[part 2 of 6: package /DBC_SysDesc_P_CANFD/Pkg_Cluster]
AUTOSAR XML (schema 4-2-2)
package /DBC_SysDesc_P_CANFD/Pkg_Cluster  (continued)
  can cluster P_CANFD: baudrate=500000, protocol-name=CAN, can-fd-baudrate=2000000  (continued)
    can physical channel P_CANFD_Channel: comm-connectors=Conn_P_CANFD_MVCU  (continued)
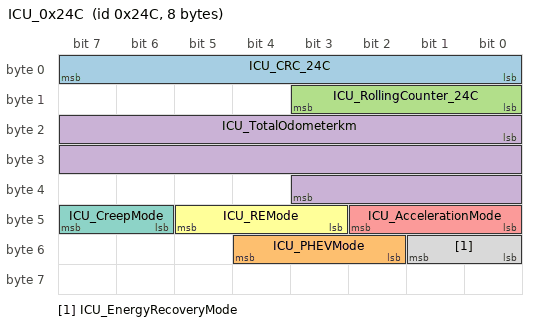
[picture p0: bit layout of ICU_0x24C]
      frame ICU_0x24C: id 0x24C, to MVCU, frame-length=8, can-addressing-mode=STANDARD, can-fd-frame-support=true, can-frame-rx-behavior=CAN-FD
        carries pdu ICU_0x24C: packing-byte-order=little-endian, start-position=0, update-indication-bit-position=-1
        pdu ICU_0x24C: length=8, transmission-mode-false-timing=cyclic-timing={time-offset=0.0, time-period=0.1}, transmission-mode-true-timing=cyclic-timing={time-offset=0.0, time-period=0.1}
          transmission-mode-conditions:
            {data-filter={data-filter-type=ALWAYS, max=255, min=0, offset=0}, i-signal-in-i-pdu=ICU_CRC_24C}
            {data-filter={data-filter-type=ALWAYS, max=7, min=0, offset=0}, i-signal-in-i-pdu=ICU_PHEVMode}
            {data-filter={data-filter-type=ALWAYS, max=15, min=0, offset=0}, i-signal-in-i-pdu=ICU_RollingCounter_24C}
            {data-filter={data-filter-type=NEW-IS-WITHIN, max=999999, min=0, offset=0}, i-signal-in-i-pdu=ICU_TotalOdometerkm}
            {data-filter={data-filter-type=ALWAYS, max=7, min=0, offset=0}, i-signal-in-i-pdu=ICU_AccelerationMode}
            {data-filter={data-filter-type=ALWAYS, max=7, min=0, offset=0}, i-signal-in-i-pdu=ICU_REMode}
            {data-filter={data-filter-type=ALWAYS, max=3, min=0, offset=0}, i-signal-in-i-pdu=ICU_CreepMode}
            {data-filter={data-filter-type=ALWAYS, max=3, min=0, offset=0}, i-signal-in-i-pdu=ICU_EnergyRecoveryMode}
          signal ICU_CRC_24C: start 0, 8 bit, little-endian, init-value=0, base-type=uint8, implementation-data-type=DT_ICU_CRC_24C, update-indication-bit-position=-1, to MVCU
          signal ICU_PHEVMode: start 50, 3 bit, little-endian, init-value=0, base-type=uint8, implementation-data-type=DT_ICU_PHEVMode, update-indication-bit-position=-1, to MVCU
          signal ICU_RollingCounter_24C: start 8, 4 bit, little-endian, init-value=0, base-type=uint8, implementation-data-type=DT_ICU_RollingCounter_24C, update-indication-bit-position=-1, to MVCU
          signal ICU_TotalOdometerkm: start 16, 20 bit, little-endian, init-value=0, base-type=uint32, implementation-data-type=DT_ICU_TotalOdometerkm, update-indication-bit-position=-1, to MVCU
          signal ICU_AccelerationMode: start 40, 3 bit, little-endian, init-value=0, base-type=uint8, implementation-data-type=DT_ICU_AccelerationMode, update-indication-bit-position=-1, to MVCU
          signal ICU_REMode: start 43, 3 bit, little-endian, init-value=0, base-type=uint8, implementation-data-type=DT_ICU_REMode, update-indication-bit-position=-1, to MVCU
          signal ICU_CreepMode: start 46, 2 bit, little-endian, init-value=0, base-type=uint8, implementation-data-type=DT_ICU_CreepMode, update-indication-bit-position=-1, to MVCU
          signal ICU_EnergyRecoveryMode: start 48, 2 bit, little-endian, init-value=0, base-type=uint8, implementation-data-type=DT_ICU_EnergyRecoveryMode, update-indication-bit-position=-1, to MVCU
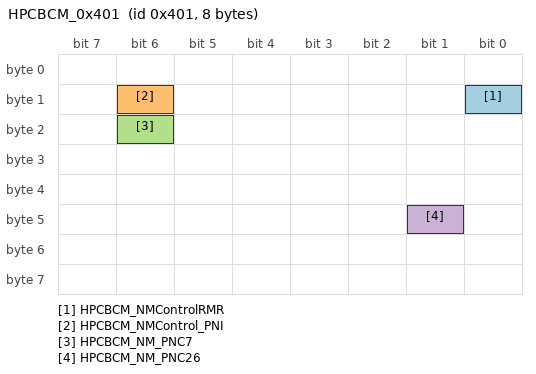
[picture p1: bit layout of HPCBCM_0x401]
      frame HPCBCM_0x401: id 0x401, to MVCU, frame-length=8, can-addressing-mode=STANDARD, can-fd-frame-support=true, can-frame-rx-behavior=CAN-FD
        carries pdu HPCBCM_0x401: packing-byte-order=little-endian, start-position=0, update-indication-bit-position=-1
        nm pdu HPCBCM_0x401: length=8, nm-data-information=false, nm-vote-information=false
          signal HPCBCM_NMControlRMR: start 8, 1 bit, little-endian, init-value=0, base-type=uint8, update-indication-bit-position=-1, to MVCU
          signal HPCBCM_NMControl_PNI: start 14, 1 bit, little-endian, init-value=0, base-type=uint8, update-indication-bit-position=-1, to MVCU
          signal HPCBCM_NM_PNC7: start 22, 1 bit, little-endian, init-value=0, base-type=uint8, update-indication-bit-position=-1, to MVCU
          signal HPCBCM_NM_PNC26: start 41, 1 bit, little-endian, init-value=0, base-type=uint8, update-indication-bit-position=-1, to MVCU
      frame IVI_0x34A: id 0x34A, to MVCU, frame-length=8, can-addressing-mode=STANDARD, can-fd-frame-support=true, can-frame-rx-behavior=CAN-FD
        carries pdu IVI_0x34A: packing-byte-order=little-endian, start-position=0, update-indication-bit-position=-1
        pdu IVI_0x34A: length=8
          transmission-mode-conditions:
            {data-filter={data-filter-type=ALWAYS, max=3, min=0, offset=0}, i-signal-in-i-pdu=IVI_DeliveryModeReq}
            {data-filter={data-filter-type=ALWAYS, max=3, min=0, offset=0}, i-signal-in-i-pdu=IVI_ShowCarModeReq}
          signal IVI_DeliveryModeReq: start 20, 2 bit, little-endian, init-value=0, base-type=uint8, implementation-data-type=DT_IVI_DeliveryModeReq, update-indication-bit-position=-1, to MVCU
          signal IVI_ShowCarModeReq: start 22, 2 bit, little-endian, init-value=0, base-type=uint8, implementation-data-type=DT_IVI_ShowCarModeReq, update-indication-bit-position=-1, to MVCU
      frame TMS_0x5A2: id 0x5A2, to MVCU, frame-length=64, can-addressing-mode=STANDARD, can-fd-frame-support=true, can-frame-rx-behavior=CAN-FD
        carries pdu TMS_0x5A2: packing-byte-order=little-endian, start-position=0, update-indication-bit-position=-1
        pdu TMS_0x5A2: length=64, transmission-mode-false-timing=cyclic-timing={time-offset=0.0, time-period=0.5}, transmission-mode-true-timing=cyclic-timing={time-offset=0.0, time-period=0.5}
          transmission-mode-conditions:
            {data-filter={data-filter-type=ALWAYS, max=250, min=0, offset=0}, i-signal-in-i-pdu=TMS_MainMotPumpSpdResp}
            {data-filter={data-filter-type=ALWAYS, max=250, min=0}, i-signal-in-i-pdu=TMS_MainMotPump_Operation_Temp}
            {data-filter={data-filter-type=ALWAYS, max=250, min=0, offset=0}, i-signal-in-i-pdu=TMS_MainMotPump_Operation_Current}
            {data-filter={data-filter-type=ALWAYS, max=254, min=0, offset=0}, i-signal-in-i-pdu=TMS_MainMotPump_Supplied_Voltage}
            {data-filter={data-filter-type=ALWAYS, max=15, min=0, offset=0}, i-signal-in-i-pdu=TMS_MainMotPumpErrSts}
          signal TMS_MainMotPumpSpdResp: start 24, 8 bit, little-endian, init-value=0, base-type=uint8, implementation-data-type=DT_TMS_MainMotPumpSpdResp, update-indication-bit-position=-1, to MVCU
          signal TMS_MainMotPump_Operation_Temp: start 32, 8 bit, little-endian, init-value=0, base-type=uint8, implementation-data-type=DT_TMS_MainMotPump_Operation_Temp, update-indication-bit-position=-1, to MVCU
          signal TMS_MainMotPump_Operation_Current: start 40, 8 bit, little-endian, init-value=0, base-type=uint8, implementation-data-type=DT_TMS_MainMotPump_Operation_Current, update-indication-bit-position=-1, to MVCU
          signal TMS_MainMotPump_Supplied_Voltage: start 48, 8 bit, little-endian, init-value=0, base-type=uint8, implementation-data-type=DT_TMS_MainMotPump_Supplied_Voltage, update-indication-bit-position=-1, to MVCU
          signal TMS_MainMotPumpErrSts: start 56, 4 bit, little-endian, init-value=0, base-type=uint8, implementation-data-type=DT_TMS_MainMotPumpErrSts, update-indication-bit-position=-1, to MVCU
      frame TMS_0x363: id 0x363, to MVCU, frame-length=16, can-addressing-mode=STANDARD, can-fd-frame-support=true, can-frame-rx-behavior=CAN-FD
        carries pdu TMS_0x363: packing-byte-order=little-endian, start-position=0, update-indication-bit-position=-1
        pdu TMS_0x363: length=16, transmission-mode-false-timing=cyclic-timing={time-offset=0.0, time-period=0.1}, transmission-mode-true-timing=cyclic-timing={time-offset=0.0, time-period=0.1}
          transmission-mode-conditions:
            {data-filter={data-filter-type=ALWAYS, max=15, min=0, offset=0}, i-signal-in-i-pdu=TMS_RollingCounter_363}
            {data-filter={data-filter-type=ALWAYS, max=1, min=0, offset=0}, i-signal-in-i-pdu=TMS_AC_Command}
            {data-filter={data-filter-type=ALWAYS, max=1, min=0, offset=0}, i-signal-in-i-pdu=TMS_PTCHeatingReq}
            {data-filter={data-filter-type=ALWAYS, max=200, min=0, offset=0}, i-signal-in-i-pdu=TMS_PTCPowerSet}
            {data-filter={data-filter-type=ALWAYS, max=1, min=0, offset=0}, i-signal-in-i-pdu=TMS_OutsideTempVD}
            {data-filter={data-filter-type=ALWAYS, max=254, min=0}, i-signal-in-i-pdu=TMS_OutsideTemp_Corrected}
          signal TMS_RollingCounter_363: start 0, 4 bit, little-endian, init-value=0, base-type=uint8, implementation-data-type=DT_TMS_RollingCounter_363, update-indication-bit-position=-1, to MVCU
          signal TMS_AC_Command: start 22, 1 bit, little-endian, init-value=0, base-type=uint8, implementation-data-type=DT_TMS_AC_Command, update-indication-bit-position=-1, to MVCU
          signal TMS_PTCHeatingReq: start 23, 1 bit, little-endian, init-value=0, base-type=uint8, implementation-data-type=DT_TMS_PTCHeatingReq, update-indication-bit-position=-1, to MVCU
          signal TMS_PTCPowerSet: start 32, 8 bit, little-endian, init-value=0, base-type=uint8, implementation-data-type=DT_TMS_PTCPowerSet, update-indication-bit-position=-1, to MVCU
          signal TMS_OutsideTempVD: start 55, 1 bit, little-endian, init-value=0, base-type=uint8, implementation-data-type=DT_TMS_OutsideTempVD, update-indication-bit-position=-1, to MVCU
          signal TMS_OutsideTemp_Corrected: start 64, 8 bit, little-endian, init-value=0, base-type=uint8, implementation-data-type=DT_TMS_OutsideTemp_Corrected, update-indication-bit-position=-1, to MVCU
      frame TMS_0x362: id 0x362, to MVCU, frame-length=32, can-addressing-mode=STANDARD, can-fd-frame-support=true, can-frame-rx-behavior=CAN-FD
        carries pdu TMS_0x362: packing-byte-order=little-endian, start-position=0, update-indication-bit-position=-1
        pdu TMS_0x362: length=32, transmission-mode-false-timing=cyclic-timing={time-offset=0.0, time-period=0.1}, transmission-mode-true-timing=cyclic-timing={time-offset=0.0, time-period=0.1}
          transmission-mode-conditions:
            {data-filter={data-filter-type=ALWAYS, max=3, min=0, offset=0}, i-signal-in-i-pdu=TMS_RAPTC_ModOprtgStsFrt}
            {data-filter={data-filter-type=ALWAYS, max=1, min=0, offset=0}, i-signal-in-i-pdu=TMS_RAPTC_ModOpEnblCmd}
            {data-filter={data-filter-type=ALWAYS, max=1023, min=0, offset=0}, i-signal-in-i-pdu=TMS_RAPTC_MsrdPwrFrt}
          signal TMS_RAPTC_ModOprtgStsFrt: start 144, 2 bit, little-endian, init-value=0, base-type=uint8, implementation-data-type=DT_TMS_RAPTC_ModOprtgStsFrt, update-indication-bit-position=-1, to MVCU
          signal TMS_RAPTC_ModOpEnblCmd: start 162, 1 bit, little-endian, init-value=0, base-type=uint8, implementation-data-type=DT_TMS_RAPTC_ModOpEnblCmd, update-indication-bit-position=-1, to MVCU
          signal TMS_RAPTC_MsrdPwrFrt: start 152, 10 bit, little-endian, init-value=0, base-type=uint16, implementation-data-type=DT_TMS_RAPTC_MsrdPwrFrt, update-indication-bit-position=-1, to MVCU
      frame ECM_0x148: id 0x148, to MVCU, frame-length=16, can-addressing-mode=STANDARD, can-fd-frame-support=true, can-frame-rx-behavior=CAN-FD
        carries pdu ECM_0x148: packing-byte-order=little-endian, start-position=0, update-indication-bit-position=-1
        pdu ECM_0x148: length=16, transmission-mode-false-timing=cyclic-timing={time-offset=0.0, time-period=1.0}, transmission-mode-true-timing=cyclic-timing={time-offset=0.0, time-period=1.0}
          transmission-mode-conditions:
            {data-filter={data-filter-type=ALWAYS, max=254, min=0, offset=0}, i-signal-in-i-pdu=ECM_SWVersionC}
            {data-filter={data-filter-type=ALWAYS, max=254, min=0, offset=0}, i-signal-in-i-pdu=ECM_SWVersionB}
            {data-filter={data-filter-type=ALWAYS, max=15, min=0, offset=0}, i-signal-in-i-pdu=ECM_SWVersionA}
            {data-filter={data-filter-type=NEW-IS-WITHIN, max=1677721600, min=0, offset=0}, i-signal-in-i-pdu=ECM_Total_fuel_consumed}
          signal ECM_SWVersionC: start 0, 8 bit, little-endian, init-value=0, base-type=uint8, implementation-data-type=DT_ECM_SWVersionC, update-indication-bit-position=-1, to MVCU
          signal ECM_SWVersionB: start 8, 8 bit, little-endian, init-value=0, base-type=uint8, implementation-data-type=DT_ECM_SWVersionB, update-indication-bit-position=-1, to MVCU
          signal ECM_SWVersionA: start 16, 4 bit, little-endian, init-value=0, base-type=uint8, implementation-data-type=DT_ECM_SWVersionA, update-indication-bit-position=-1, to MVCU
          signal ECM_Total_fuel_consumed: start 64, 32 bit, little-endian, init-value=0, base-type=uint32, implementation-data-type=DT_ECM_Total_fuel_consumed, update-indication-bit-position=-1, to MVCU
      frame IBS_0x225: id 0x225, to MVCU, frame-length=32, can-addressing-mode=STANDARD, can-fd-frame-support=true, can-frame-rx-behavior=CAN-FD
        carries pdu IBS_0x225: packing-byte-order=little-endian, start-position=0, update-indication-bit-position=-1
        pdu IBS_0x225: length=32, transmission-mode-false-timing=cyclic-timing={time-offset=0.0, time-period=0.02}, transmission-mode-true-timing=cyclic-timing={time-offset=0.0, time-period=0.02}
          transmission-mode-conditions:
            {data-filter={data-filter-type=ALWAYS, max=255, min=0, offset=0}, i-signal-in-i-pdu=IBS_CRC_225}
            {data-filter={data-filter-type=ALWAYS, max=15, min=0, offset=0}, i-signal-in-i-pdu=IBS_RollingCounter_225}
            {data-filter={data-filter-type=ALWAYS, max=3, min=0, offset=0}, i-signal-in-i-pdu=IBS_Warning_Level}
          signal IBS_CRC_225: start 0, 8 bit, little-endian, init-value=0, base-type=uint8, implementation-data-type=DT_IBS_CRC_225, update-indication-bit-position=-1, to MVCU
          signal IBS_RollingCounter_225: start 8, 4 bit, little-endian, init-value=0, base-type=uint8, implementation-data-type=DT_IBS_RollingCounter_225, update-indication-bit-position=-1, to MVCU
          signal IBS_Warning_Level: start 46, 2 bit, little-endian, init-value=0, base-type=uint8, implementation-data-type=DT_IBS_Warning_Level, update-indication-bit-position=-1, to MVCU
      frame HPCGW_0x3B1: id 0x3B1, to MVCU, frame-length=32, can-addressing-mode=STANDARD, can-fd-frame-support=true, can-frame-rx-behavior=CAN-FD
        carries pdu HPCGW_0x3B1: packing-byte-order=little-endian, start-position=0, update-indication-bit-position=-1
        pdu HPCGW_0x3B1: length=32, transmission-mode-false-timing=cyclic-timing={time-offset=0.0, time-period=0.1}, transmission-mode-true-timing=cyclic-timing={time-offset=0.0, time-period=0.1}
          transmission-mode-conditions:
            {data-filter={data-filter-type=ALWAYS, max=255, min=0, offset=0}, i-signal-in-i-pdu=GW_CRC_3B1}
            {data-filter={data-filter-type=ALWAYS, max=15, min=0, offset=0}, i-signal-in-i-pdu=GW_RollingCounter_3B1}
            {data-filter={data-filter-type=ALWAYS, max=3, min=0, offset=0}, i-signal-in-i-pdu=GW_ACU_FLSeatBeltRSt}
            {data-filter={data-filter-type=ALWAYS, max=3, min=0, offset=0}, i-signal-in-i-pdu=GW_ACU_FRSeatBeltRSt}
            {data-filter={data-filter-type=ALWAYS, max=7, min=0, offset=0}, i-signal-in-i-pdu=GW_IBC_EPB_Status}
            {data-filter={data-filter-type=ALWAYS, max=1, min=0, offset=0}, i-signal-in-i-pdu=GW_ACU_TotalCrashOutputSts}
            {data-filter={data-filter-type=ALWAYS, max=250, min=0}, i-signal-in-i-pdu=GW_BZCU_DCChgExitTemp_Pos}
            {data-filter={data-filter-type=ALWAYS, max=250, min=0}, i-signal-in-i-pdu=GW_BZCU_DCChgExitTemp_Neg}
            {data-filter={data-filter-type=ALWAYS, max=250, min=0}, i-signal-in-i-pdu=GW_BZCU_ACChgExitTemp_Pos}
            {data-filter={data-filter-type=ALWAYS, max=1, min=0, offset=0}, i-signal-in-i-pdu=GW_BZCU_FuelTankSts}
            {data-filter={data-filter-type=ALWAYS, max=180, min=0, offset=0}, i-signal-in-i-pdu=GW_BZCU_LBMS_VoltA}
            {data-filter={data-filter-type=ALWAYS, max=250, min=0}, i-signal-in-i-pdu=GW_BZCU_ACChgExitTemp_Neg}
            {data-filter={data-filter-type=ALWAYS, max=3, min=0, offset=0}, i-signal-in-i-pdu=GW_BZCU_FuelTankStsLockSts}
            {data-filter={data-filter-type=ALWAYS, max=3, min=0, offset=0}, i-signal-in-i-pdu=GW_BZCU_FuelTankLockCtrl}
            {data-filter={data-filter-type=ALWAYS, max=3, min=0, offset=0}, i-signal-in-i-pdu=GW_BZCU_ACChgLockSts}
            {data-filter={data-filter-type=ALWAYS, max=1, min=0, offset=0}, i-signal-in-i-pdu=GW_RZCU_Cabin_220Vconnect_Sts}
            {data-filter={data-filter-type=ALWAYS, max=1, min=0, offset=0}, i-signal-in-i-pdu=GW_BZCU_Cab_220VRelay_CtrlSts}
            {data-filter={data-filter-type=ALWAYS, max=1, min=0, offset=0}, i-signal-in-i-pdu=GW_BZCU_Cab_PDU220VRelay_CtrlSts}
            {data-filter={data-filter-type=ALWAYS, max=1, min=0, offset=0}, i-signal-in-i-pdu=GW_BZCU_Cabin_220VRelay_CtrlSts}
            {data-filter={data-filter-type=ALWAYS, max=1, min=0, offset=0}, i-signal-in-i-pdu=GW_BZCU_Cab_220Vconnect_Sts}
            {data-filter={data-filter-type=NEW-IS-WITHIN, max=11000, min=0}, i-signal-in-i-pdu=GW_TBOXSOC_Altitude}
          signal GW_CRC_3B1: start 0, 8 bit, little-endian, init-value=0, base-type=uint8, implementation-data-type=DT_GW_CRC_3B1, update-indication-bit-position=-1, to MVCU
          signal GW_RollingCounter_3B1: start 8, 4 bit, little-endian, init-value=0, base-type=uint8, implementation-data-type=DT_GW_RollingCounter_3B1, update-indication-bit-position=-1, to MVCU
          signal GW_ACU_FLSeatBeltRSt: start 16, 2 bit, little-endian, init-value=0, base-type=uint8, implementation-data-type=DT_GW_ACU_FLSeatBeltRSt, update-indication-bit-position=-1, to MVCU
          signal GW_ACU_FRSeatBeltRSt: start 18, 2 bit, little-endian, init-value=0, base-type=uint8, implementation-data-type=DT_GW_ACU_FRSeatBeltRSt, update-indication-bit-position=-1, to MVCU
          signal GW_IBC_EPB_Status: start 20, 3 bit, little-endian, init-value=0, base-type=uint8, implementation-data-type=DT_GW_IBC_EPB_Status, update-indication-bit-position=-1, to MVCU
          signal GW_ACU_TotalCrashOutputSts: start 40, 1 bit, little-endian, init-value=0, base-type=uint8, implementation-data-type=DT_GW_ACU_TotalCrashOutputSts, update-indication-bit-position=-1, to MVCU
          signal GW_BZCU_DCChgExitTemp_Pos: start 56, 8 bit, little-endian, init-value=0, base-type=uint8, implementation-data-type=DT_GW_BZCU_DCChgExitTemp_Pos, update-indication-bit-position=-1, to MVCU
          signal GW_BZCU_DCChgExitTemp_Neg: start 64, 8 bit, little-endian, init-value=0, base-type=uint8, implementation-data-type=DT_GW_BZCU_DCChgExitTemp_Neg, update-indication-bit-position=-1, to MVCU
          signal GW_BZCU_ACChgExitTemp_Pos: start 72, 8 bit, little-endian, init-value=0, base-type=uint8, implementation-data-type=DT_GW_BZCU_ACChgExitTemp_Pos, update-indication-bit-position=-1, to MVCU
          signal GW_BZCU_FuelTankSts: start 94, 1 bit, little-endian, init-value=0, base-type=uint8, implementation-data-type=DT_GW_BZCU_FuelTankSts, update-indication-bit-position=-1, to MVCU
          signal GW_BZCU_LBMS_VoltA: start 136, 8 bit, little-endian, init-value=0, base-type=uint8, implementation-data-type=DT_GW_BZCU_LBMS_VoltA, update-indication-bit-position=-1, to MVCU
          signal GW_BZCU_ACChgExitTemp_Neg: start 152, 8 bit, little-endian, init-value=0, base-type=uint8, implementation-data-type=DT_GW_BZCU_ACChgExitTemp_Neg, update-indication-bit-position=-1, to MVCU
          signal GW_BZCU_FuelTankStsLockSts: start 204, 2 bit, little-endian, init-value=0, base-type=uint8, implementation-data-type=DT_GW_BZCU_FuelTankStsLockSts, update-indication-bit-position=-1, to MVCU
          signal GW_BZCU_FuelTankLockCtrl: start 206, 2 bit, little-endian, init-value=0, base-type=uint8, implementation-data-type=DT_GW_BZCU_FuelTankLockCtrl, update-indication-bit-position=-1, to MVCU
          signal GW_BZCU_ACChgLockSts: start 208, 2 bit, little-endian, init-value=0, base-type=uint8, implementation-data-type=DT_GW_BZCU_ACChgLockSts, update-indication-bit-position=-1, to MVCU
          signal GW_RZCU_Cabin_220Vconnect_Sts: start 210, 1 bit, little-endian, init-value=0, base-type=uint8, implementation-data-type=DT_GW_RZCU_Cabin_220Vconnect_Sts, update-indication-bit-position=-1, to MVCU
          signal GW_BZCU_Cab_220VRelay_CtrlSts: start 211, 1 bit, little-endian, init-value=0, base-type=uint8, implementation-data-type=DT_GW_BZCU_Cab_220VRelay_CtrlSts, update-indication-bit-position=-1, to MVCU
          signal GW_BZCU_Cab_PDU220VRelay_CtrlSts: start 212, 1 bit, little-endian, init-value=0, base-type=uint8, implementation-data-type=DT_GW_BZCU_Cab_PDU220VRelay_CtrlSts, update-indication-bit-position=-1, to MVCU
          signal GW_BZCU_Cabin_220VRelay_CtrlSts: start 213, 1 bit, little-endian, init-value=0, base-type=uint8, implementation-data-type=DT_GW_BZCU_Cabin_220VRelay_CtrlSts, update-indication-bit-position=-1, to MVCU
          signal GW_BZCU_Cab_220Vconnect_Sts: start 214, 1 bit, little-endian, init-value=0, base-type=uint8, implementation-data-type=DT_GW_BZCU_Cab_220Vconnect_Sts, update-indication-bit-position=-1, to MVCU
          signal GW_TBOXSOC_Altitude: start 236, 14 bit, little-endian, init-value=0, base-type=uint16, implementation-data-type=DT_GW_TBOXSOC_Altitude, update-indication-bit-position=-1, to MVCU
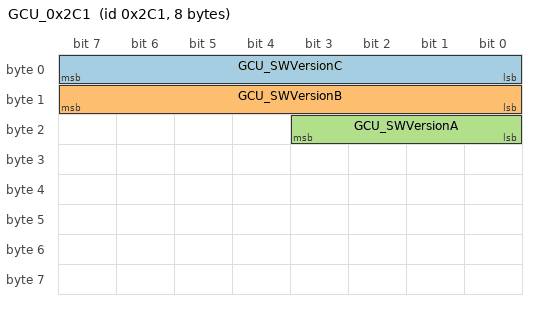
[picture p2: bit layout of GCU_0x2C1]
      frame GCU_0x2C1: id 0x2C1, to MVCU, frame-length=8, can-addressing-mode=STANDARD, can-fd-frame-support=true, can-frame-rx-behavior=CAN-FD
        carries pdu GCU_0x2C1: packing-byte-order=little-endian, start-position=0, update-indication-bit-position=-1
        pdu GCU_0x2C1: length=8, transmission-mode-false-timing=cyclic-timing={time-offset=0.0, time-period=0.1}, transmission-mode-true-timing=cyclic-timing={time-offset=0.0, time-period=0.1}
          transmission-mode-conditions:
            {data-filter={data-filter-type=ALWAYS, max=254, min=0, offset=0}, i-signal-in-i-pdu=GCU_SWVersionC}
            {data-filter={data-filter-type=ALWAYS, max=254, min=0, offset=0}, i-signal-in-i-pdu=GCU_SWVersionB}
            {data-filter={data-filter-type=ALWAYS, max=15, min=0, offset=0}, i-signal-in-i-pdu=GCU_SWVersionA}
          signal GCU_SWVersionC: start 0, 8 bit, little-endian, init-value=0, base-type=uint8, implementation-data-type=DT_GCU_SWVersionC, update-indication-bit-position=-1, to MVCU
          signal GCU_SWVersionB: start 8, 8 bit, little-endian, init-value=0, base-type=uint8, implementation-data-type=DT_GCU_SWVersionB, update-indication-bit-position=-1, to MVCU
          signal GCU_SWVersionA: start 16, 4 bit, little-endian, init-value=0, base-type=uint8, implementation-data-type=DT_GCU_SWVersionA, update-indication-bit-position=-1, to MVCU
      frame DCDC_0x324: id 0x324, to MVCU, frame-length=16, can-addressing-mode=STANDARD, can-fd-frame-support=true, can-frame-rx-behavior=CAN-FD
        carries pdu DCDC_0x324: packing-byte-order=little-endian, start-position=0, update-indication-bit-position=-1
        pdu DCDC_0x324: length=16, transmission-mode-false-timing=cyclic-timing={time-offset=0.0, time-period=0.1}, transmission-mode-true-timing=cyclic-timing={time-offset=0.0, time-period=0.1}
          transmission-mode-conditions:
            {data-filter={data-filter-type=ALWAYS, max=255, min=0, offset=0}, i-signal-in-i-pdu=DCDC_CRC_324}
            {data-filter={data-filter-type=ALWAYS, max=15, min=0, offset=0}, i-signal-in-i-pdu=DCDC_RollingCounter_324}
            {data-filter={data-filter-type=ALWAYS, max=3, min=0, offset=0}, i-signal-in-i-pdu=DCDC_WorkSts}
            {data-filter={data-filter-type=ALWAYS, max=1, min=0, offset=0}, i-signal-in-i-pdu=DCDC_Under_Output_Voltage}
            {data-filter={data-filter-type=ALWAYS, max=1, min=0, offset=0}, i-signal-in-i-pdu=DCDC_Over_Output_Voltage}
            {data-filter={data-filter-type=ALWAYS, max=1, min=0, offset=0}, i-signal-in-i-pdu=DCDC_Under_Input_Voltage}
            {data-filter={data-filter-type=ALWAYS, max=1, min=0, offset=0}, i-signal-in-i-pdu=DCDC_Over_Input_Voltage}
            {data-filter={data-filter-type=ALWAYS, max=1, min=0, offset=0}, i-signal-in-i-pdu=DCDC_Over_Input_Current}
            {data-filter={data-filter-type=NEW-IS-WITHIN, max=2500, min=0, offset=0}, i-signal-in-i-pdu=DCDC_Real_Output_Current}
            {data-filter={data-filter-type=NEW-IS-WITHIN, max=500, min=0, offset=0}, i-signal-in-i-pdu=DCDC_Real_Output_Voltage}
            {data-filter={data-filter-type=ALWAYS, max=100, min=0, offset=0}, i-signal-in-i-pdu=DCDC_Real_Input_Current}
            {data-filter={data-filter-type=NEW-IS-WITHIN, max=5000, min=0, offset=0}, i-signal-in-i-pdu=DCDC_Real_Input_Voltage}
            {data-filter={data-filter-type=ALWAYS, max=1, min=0, offset=0}, i-signal-in-i-pdu=DCDC_Derating}
            {data-filter={data-filter-type=ALWAYS, max=1, min=0, offset=0}, i-signal-in-i-pdu=DCDC_Hardware_Fault_Flag}
            {data-filter={data-filter-type=ALWAYS, max=1, min=0, offset=0}, i-signal-in-i-pdu=CDU_ACChg_HIVSts}
            {data-filter={data-filter-type=ALWAYS, max=1, min=0, offset=0}, i-signal-in-i-pdu=CDU_OBC_OverTemp}
            {data-filter={data-filter-type=ALWAYS, max=1, min=0, offset=0}, i-signal-in-i-pdu=CDU_SelfCheckSt}
            {data-filter={data-filter-type=ALWAYS, max=1, min=0, offset=0}, i-signal-in-i-pdu=CDU_HV_HIVSts}
          signal DCDC_CRC_324: start 0, 8 bit, little-endian, init-value=0, base-type=uint8, implementation-data-type=DT_DCDC_CRC_324, update-indication-bit-position=-1, to MVCU
          signal DCDC_RollingCounter_324: start 8, 4 bit, little-endian, init-value=0, base-type=uint8, implementation-data-type=DT_DCDC_RollingCounter_324, update-indication-bit-position=-1, to MVCU
          signal DCDC_WorkSts: start 16, 3 bit, little-endian, init-value=0, base-type=uint8, implementation-data-type=DT_DCDC_WorkSts, update-indication-bit-position=-1, to MVCU
          signal DCDC_Under_Output_Voltage: start 19, 1 bit, little-endian, init-value=0, base-type=uint8, implementation-data-type=DT_DCDC_Under_Output_Voltage, update-indication-bit-position=-1, to MVCU
          signal DCDC_Over_Output_Voltage: start 20, 1 bit, little-endian, init-value=0, base-type=uint8, implementation-data-type=DT_DCDC_Over_Output_Voltage, update-indication-bit-position=-1, to MVCU
          signal DCDC_Under_Input_Voltage: start 21, 1 bit, little-endian, init-value=0, base-type=uint8, implementation-data-type=DT_DCDC_Under_Input_Voltage, update-indication-bit-position=-1, to MVCU
          signal DCDC_Over_Input_Voltage: start 22, 1 bit, little-endian, init-value=0, base-type=uint8, implementation-data-type=DT_DCDC_Over_Input_Voltage, update-indication-bit-position=-1, to MVCU
          signal DCDC_Over_Input_Current: start 23, 1 bit, little-endian, init-value=0, base-type=uint8, implementation-data-type=DT_DCDC_Over_Input_Current, update-indication-bit-position=-1, to MVCU
          signal DCDC_Real_Output_Current: start 24, 12 bit, little-endian, init-value=0, base-type=uint16, implementation-data-type=DT_DCDC_Real_Output_Current, update-indication-bit-position=-1, to MVCU
          signal DCDC_Real_Output_Voltage: start 36, 12 bit, little-endian, init-value=0, base-type=uint16, implementation-data-type=DT_DCDC_Real_Output_Voltage, update-indication-bit-position=-1, to MVCU
          signal DCDC_Real_Input_Current: start 48, 8 bit, little-endian, init-value=0, base-type=uint8, implementation-data-type=DT_DCDC_Real_Input_Current, update-indication-bit-position=-1, to MVCU
          signal DCDC_Real_Input_Voltage: start 56, 13 bit, little-endian, init-value=0, base-type=uint16, implementation-data-type=DT_DCDC_Real_Input_Voltage, update-indication-bit-position=-1, to MVCU
          signal DCDC_Derating: start 69, 1 bit, little-endian, init-value=0, base-type=uint8, implementation-data-type=DT_DCDC_Derating, update-indication-bit-position=-1, to MVCU
          signal DCDC_Hardware_Fault_Flag: start 71, 1 bit, little-endian, init-value=0, base-type=uint8, implementation-data-type=DT_DCDC_Hardware_Fault_Flag, update-indication-bit-position=-1, to MVCU
          signal CDU_ACChg_HIVSts: start 83, 1 bit, little-endian, init-value=0, base-type=uint8, implementation-data-type=DT_CDU_ACChg_HIVSts, update-indication-bit-position=-1, to MVCU
          signal CDU_OBC_OverTemp: start 90, 1 bit, little-endian, init-value=0, base-type=uint8, implementation-data-type=DT_CDU_OBC_OverTemp, update-indication-bit-position=-1, to MVCU
          signal CDU_SelfCheckSt: start 112, 1 bit, little-endian, init-value=0, base-type=uint8, implementation-data-type=DT_CDU_SelfCheckSt, update-indication-bit-position=-1, to MVCU
          signal CDU_HV_HIVSts: start 113, 1 bit, little-endian, init-value=0, base-type=uint8, implementation-data-type=DT_CDU_HV_HIVSts, update-indication-bit-position=-1, to MVCU
      frame UDS_Phy_Rx_721_MCUM: id 0x721, to MVCU, frame-length=64, can-addressing-mode=STANDARD, can-fd-frame-support=true, can-frame-rx-behavior=CAN-FD
        carries pdu UDS_Phy_Rx_721_MCUM: packing-byte-order=big-endian, start-position=7, update-indication-bit-position=-1
        dcm i pdu UDS_Phy_Rx_721_MCUM: length=64, diag-pdu-type=DIAG-REQUEST
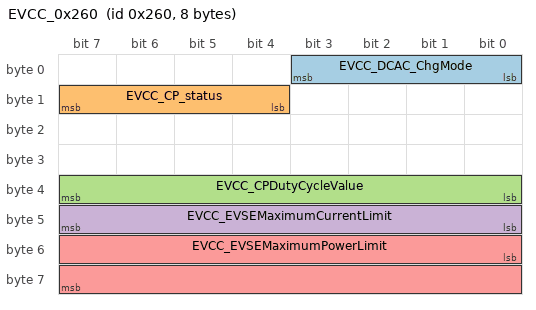
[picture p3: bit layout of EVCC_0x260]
      frame EVCC_0x260: id 0x260, to MVCU, frame-length=8, can-addressing-mode=STANDARD, can-fd-frame-support=true, can-frame-rx-behavior=CAN-FD
        carries pdu EVCC_0x260: packing-byte-order=little-endian, start-position=0, update-indication-bit-position=-1
        pdu EVCC_0x260: length=8, transmission-mode-false-timing=cyclic-timing={time-offset=0.0, time-period=0.1}, transmission-mode-true-timing=cyclic-timing={time-offset=0.0, time-period=0.1}
          transmission-mode-conditions:
            {data-filter={data-filter-type=ALWAYS, max=14, min=0, offset=0}, i-signal-in-i-pdu=EVCC_DCAC_ChgMode}
            {data-filter={data-filter-type=ALWAYS, max=14, min=0, offset=0}, i-signal-in-i-pdu=EVCC_CP_status}
            {data-filter={data-filter-type=ALWAYS, max=100, min=0, offset=0}, i-signal-in-i-pdu=EVCC_CPDutyCycleValue}
            {data-filter={data-filter-type=ALWAYS, max=254, min=0, offset=0}, i-signal-in-i-pdu=EVCC_EVSEMaximumCurrentLimit}
            {data-filter={data-filter-type=NEW-IS-WITHIN, max=65000, min=0, offset=0}, i-signal-in-i-pdu=EVCC_EVSEMaximumPowerLimit}
          signal EVCC_DCAC_ChgMode: start 0, 4 bit, little-endian, init-value=0, base-type=uint8, implementation-data-type=DT_EVCC_DCAC_ChgMode, update-indication-bit-position=-1, to MVCU
          signal EVCC_CP_status: start 12, 4 bit, little-endian, init-value=0, base-type=uint8, implementation-data-type=DT_EVCC_CP_status, update-indication-bit-position=-1, to MVCU
          signal EVCC_CPDutyCycleValue: start 32, 8 bit, little-endian, init-value=0, base-type=uint8, implementation-data-type=DT_EVCC_CPDutyCycleValue, update-indication-bit-position=-1, to MVCU
          signal EVCC_EVSEMaximumCurrentLimit: start 40, 8 bit, little-endian, init-value=0, base-type=uint8, implementation-data-type=DT_EVCC_EVSEMaximumCurrentLimit, update-indication-bit-position=-1, to MVCU
          signal EVCC_EVSEMaximumPowerLimit: start 48, 16 bit, little-endian, init-value=0, base-type=uint16, implementation-data-type=DT_EVCC_EVSEMaximumPowerLimit, update-indication-bit-position=-1, to MVCU
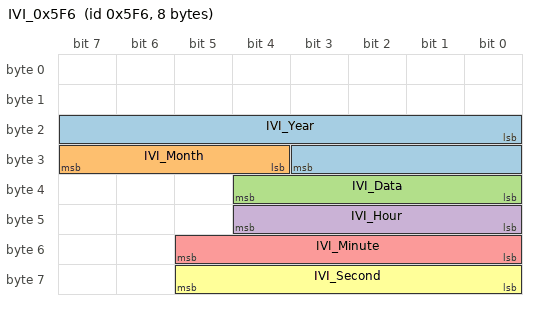
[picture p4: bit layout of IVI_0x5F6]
      frame IVI_0x5F6: id 0x5F6, to MVCU, frame-length=8, can-addressing-mode=STANDARD, can-fd-frame-support=true, can-frame-rx-behavior=CAN-FD
        carries pdu IVI_0x5F6: packing-byte-order=little-endian, start-position=0, update-indication-bit-position=-1
        pdu IVI_0x5F6: length=8, transmission-mode-false-timing=cyclic-timing={time-offset=0.0, time-period=0.5}, transmission-mode-true-timing=cyclic-timing={time-offset=0.0, time-period=0.5}
          transmission-mode-conditions:
            {data-filter={data-filter-type=NEW-IS-WITHIN, max=4094, min=0, offset=0}, i-signal-in-i-pdu=IVI_Year}
            {data-filter={data-filter-type=ALWAYS, max=12, min=0, offset=0}, i-signal-in-i-pdu=IVI_Month}
            {data-filter={data-filter-type=ALWAYS, max=31, min=0, offset=0}, i-signal-in-i-pdu=IVI_Data}
            {data-filter={data-filter-type=ALWAYS, max=23, min=0, offset=0}, i-signal-in-i-pdu=IVI_Hour}
            {data-filter={data-filter-type=ALWAYS, max=59, min=0, offset=0}, i-signal-in-i-pdu=IVI_Minute}
            {data-filter={data-filter-type=ALWAYS, max=59, min=0, offset=0}, i-signal-in-i-pdu=IVI_Second}
          signal IVI_Year: start 16, 12 bit, little-endian, init-value=0, base-type=uint16, implementation-data-type=DT_IVI_Year, update-indication-bit-position=-1, to MVCU
          signal IVI_Month: start 28, 4 bit, little-endian, init-value=0, base-type=uint8, implementation-data-type=DT_IVI_Month, update-indication-bit-position=-1, to MVCU
          signal IVI_Data: start 32, 5 bit, little-endian, init-value=0, base-type=uint8, implementation-data-type=DT_IVI_Data, update-indication-bit-position=-1, to MVCU
          signal IVI_Hour: start 40, 5 bit, little-endian, init-value=0, base-type=uint8, implementation-data-type=DT_IVI_Hour, update-indication-bit-position=-1, to MVCU
          signal IVI_Minute: start 48, 6 bit, little-endian, init-value=0, base-type=uint8, implementation-data-type=DT_IVI_Minute, update-indication-bit-position=-1, to MVCU
          signal IVI_Second: start 56, 6 bit, little-endian, init-value=0, base-type=uint8, implementation-data-type=DT_IVI_Second, update-indication-bit-position=-1, to MVCU
      frame MCU_0x5CB: id 0x5CB, from MVCU, frame-length=8, can-addressing-mode=STANDARD, can-fd-frame-support=true, can-frame-tx-behavior=CAN-FD
        carries pdu MCU_0x5CB: packing-byte-order=little-endian, start-position=0, update-indication-bit-position=-1
        pdu MCU_0x5CB: length=8, transmission-mode-false-timing=cyclic-timing={time-offset=0.0, time-period=0.01}, transmission-mode-true-timing=cyclic-timing={time-offset=0.0, time-period=0.01}
          transmission-mode-conditions:
            {data-filter={data-filter-type=ALWAYS, max=2, min=0, offset=0}, i-signal-in-i-pdu=GTC_TestSts}
            {data-filter={data-filter-type=NEW-IS-WITHIN, max=36000, min=0, offset=0}, i-signal-in-i-pdu=GTC_ThetaPos}
            {data-filter={data-filter-type=NEW-IS-WITHIN, max=36000, min=0, offset=0}, i-signal-in-i-pdu=GTC_ThetaNeg}
            {data-filter={data-filter-type=NEW-IS-WITHIN, max=36000, min=0, offset=0}, i-signal-in-i-pdu=GTC_ThetaDelt}
            {data-filter={data-filter-type=ALWAYS, max=1, min=0, offset=0}, i-signal-in-i-pdu=GTC_TestRslt}
            {data-filter={data-filter-type=ALWAYS, max=2, min=0, offset=0}, i-signal-in-i-pdu=MCUMR_GTC_TestSts}
            {data-filter={data-filter-type=NEW-IS-WITHIN, max=36000, min=0, offset=0}, i-signal-in-i-pdu=MCUMR_GTC_ThetaPos}
            {data-filter={data-filter-type=NEW-IS-WITHIN, max=36000, min=0, offset=0}, i-signal-in-i-pdu=MCUMR_GTC_ThetaNeg}
            {data-filter={data-filter-type=NEW-IS-WITHIN, max=36000, min=0, offset=0}, i-signal-in-i-pdu=MCUMR_GTC_ThetaDelt}
            {data-filter={data-filter-type=ALWAYS, max=1, min=0, offset=0}, i-signal-in-i-pdu=MCUMR_GTC_TestRslt}
          signal GTC_TestSts: start 0, 8 bit, little-endian, init-value=0, base-type=uint8, implementation-data-type=DT_GTC_TestSts, update-indication-bit-position=-1
          signal GTC_ThetaPos: start 8, 16 bit, little-endian, init-value=0, base-type=uint16, implementation-data-type=DT_GTC_ThetaPos, update-indication-bit-position=-1
          signal GTC_ThetaNeg: start 24, 16 bit, little-endian, init-value=0, base-type=uint16, implementation-data-type=DT_GTC_ThetaNeg, update-indication-bit-position=-1
          signal GTC_ThetaDelt: start 40, 16 bit, little-endian, init-value=0, base-type=uint16, implementation-data-type=DT_GTC_ThetaDelt, update-indication-bit-position=-1
          signal GTC_TestRslt: start 56, 8 bit, little-endian, init-value=0, base-type=uint8, implementation-data-type=DT_GTC_TestRslt, update-indication-bit-position=-1
          signal MCUMR_GTC_TestSts: start 64, 8 bit, little-endian, init-value=0, base-type=uint8, implementation-data-type=DT_MCUMR_GTC_TestSts, update-indication-bit-position=-1
          signal MCUMR_GTC_ThetaPos: start 72, 16 bit, little-endian, init-value=0, base-type=uint16, implementation-data-type=DT_MCUMR_GTC_ThetaPos, update-indication-bit-position=-1
          signal MCUMR_GTC_ThetaNeg: start 88, 16 bit, little-endian, init-value=0, base-type=uint16, implementation-data-type=DT_MCUMR_GTC_ThetaNeg, update-indication-bit-position=-1
          signal MCUMR_GTC_ThetaDelt: start 104, 16 bit, little-endian, init-value=0, base-type=uint16, implementation-data-type=DT_MCUMR_GTC_ThetaDelt, update-indication-bit-position=-1
          signal MCUMR_GTC_TestRslt: start 120, 8 bit, little-endian, init-value=0, base-type=uint8, implementation-data-type=DT_MCUMR_GTC_TestRslt, update-indication-bit-position=-1
      frame MCU_0x5CA: id 0x5CA, from MVCU, frame-length=32, can-addressing-mode=STANDARD, can-fd-frame-support=true, can-frame-tx-behavior=CAN-FD
        carries pdu MCU_0x5CA: packing-byte-order=little-endian, start-position=0, update-indication-bit-position=-1
        pdu MCU_0x5CA: length=32, transmission-mode-false-timing=cyclic-timing={time-offset=0.0, time-period=0.01}, transmission-mode-true-timing=cyclic-timing={time-offset=0.0, time-period=0.01}
          transmission-mode-conditions:
            {data-filter={data-filter-type=NEW-IS-WITHIN, max=4048, min=48}, i-signal-in-i-pdu=EddyCur_Para_Cos_m}
            {data-filter={data-filter-type=ALWAYS, max=5, min=0, offset=0}, i-signal-in-i-pdu=EddyCur_Stage}
            {data-filter={data-filter-type=ALWAYS, max=1, min=0, offset=0}, i-signal-in-i-pdu=EddyCur_IdenFinish_Flag}
            {data-filter={data-filter-type=NEW-IS-WITHIN, max=4048, min=48}, i-signal-in-i-pdu=EddyCur_Para_Sin_m}
            {data-filter={data-filter-type=ALWAYS, max=1, min=0, offset=0}, i-signal-in-i-pdu=EddyCur_Write_Flag}
            {data-filter={data-filter-type=ALWAYS, max=1, min=0, offset=0}, i-signal-in-i-pdu=EddyCur_FauPro_IDEL_OTime_Flag}
            {data-filter={data-filter-type=ALWAYS, max=1, min=0, offset=0}, i-signal-in-i-pdu=EddyCur_FauPro_SpdInstab_Flag}
            {data-filter={data-filter-type=ALWAYS, max=1, min=0, offset=0}, i-signal-in-i-pdu=EddyCur_FauPro_IDPara_OVal_Flag}
            {data-filter={data-filter-type=NEW-IS-WITHIN, max=30000, min=0, offset=0}, i-signal-in-i-pdu=EddyCur_Para_Cos_k}
            {data-filter={data-filter-type=ALWAYS, max=1, min=0, offset=0}, i-signal-in-i-pdu=EddyCur_Enable}
            {data-filter={data-filter-type=NEW-IS-WITHIN, max=30000, min=0, offset=0}, i-signal-in-i-pdu=EddyCur_Para_Sin_k}
            {data-filter={data-filter-type=ALWAYS, max=1, min=0, offset=0}, i-signal-in-i-pdu=EddyCur_IdenFail_Flag}
            {data-filter={data-filter-type=NEW-IS-WITHIN, max=40000, min=0}, i-signal-in-i-pdu=EddyCur_Para_Cos_Pha}
            {data-filter={data-filter-type=NEW-IS-WITHIN, max=40000, min=0}, i-signal-in-i-pdu=EddyCur_Para_Sin_Pha}
            {data-filter={data-filter-type=ALWAYS, max=1, min=0, offset=0}, i-signal-in-i-pdu=EddyCur_ReadSuccess_Flag}
            {data-filter={data-filter-type=ALWAYS, max=1, min=0, offset=0}, i-signal-in-i-pdu=OfsIden_ReadSuccess_Flag}
            {data-filter={data-filter-type=ALWAYS, max=1, min=0, offset=0}, i-signal-in-i-pdu=OfsIden_SpdUp_Overtime}
            {data-filter={data-filter-type=ALWAYS, max=1, min=0, offset=0}, i-signal-in-i-pdu=OfsIden_SpdUp_OverSpd}
            {data-filter={data-filter-type=ALWAYS, max=1, min=0, offset=0}, i-signal-in-i-pdu=OfsIden_IdenDiverge}
            {data-filter={data-filter-type=ALWAYS, max=1, min=0, offset=0}, i-signal-in-i-pdu=OfsIden_IdenCntOver}
            {data-filter={data-filter-type=ALWAYS, max=1, min=0, offset=0}, i-signal-in-i-pdu=OfsIden_MtrLock}
            {data-filter={data-filter-type=NEW-IS-WITHIN, max=3600, min=0, offset=0}, i-signal-in-i-pdu=OfsIden_OfsRslt}
            {data-filter={data-filter-type=ALWAYS, max=7, min=0, offset=0}, i-signal-in-i-pdu=OfsIden_Sts}
            {data-filter={data-filter-type=ALWAYS, max=1, min=0, offset=0}, i-signal-in-i-pdu=OfsIden_Finish}
            {data-filter={data-filter-type=ALWAYS, max=1, min=0, offset=0}, i-signal-in-i-pdu=OfsIden_OfsWrite_Finish}
            {data-filter={data-filter-type=ALWAYS, max=1, min=0, offset=0}, i-signal-in-i-pdu=OfsIden_DirWrite_Finish}
            {data-filter={data-filter-type=ALWAYS, max=2, min=0}, i-signal-in-i-pdu=OfsIden_DirIden_Rslt}
            {data-filter={data-filter-type=ALWAYS, max=1, min=0, offset=0}, i-signal-in-i-pdu=OfsIden_ZeroAlign_OverTime}
            {data-filter={data-filter-type=ALWAYS, max=1, min=0, offset=0}, i-signal-in-i-pdu=OfsIden_ZeroAlign_Fail}
            {data-filter={data-filter-type=ALWAYS, max=1, min=0, offset=0}, i-signal-in-i-pdu=OfsIden_IFStart_Overtime}
            {data-filter={data-filter-type=ALWAYS, max=1, min=0, offset=0}, i-signal-in-i-pdu=OfsIden_IFStart_Fail}
            {data-filter={data-filter-type=NEW-IS-WITHIN, max=60000, min=0}, i-signal-in-i-pdu=PosDly_Cal_RslvDelayTime}
            {data-filter={data-filter-type=NEW-IS-WITHIN, max=20000, min=0}, i-signal-in-i-pdu=PosDly_Theta_k_Std}
            {data-filter={data-filter-type=ALWAYS, max=1, min=0, offset=0}, i-signal-in-i-pdu=PosDly_Supplier}
            {data-filter={data-filter-type=ALWAYS, max=1, min=0, offset=0}, i-signal-in-i-pdu=PosDly_FauPro_Ident_OTm_Flag}
            {data-filter={data-filter-type=ALWAYS, max=1, min=0, offset=0}, i-signal-in-i-pdu=PosDly_FauPro_SpdDn_OTm_Flag}
            {data-filter={data-filter-type=ALWAYS, max=60, min=0}, i-signal-in-i-pdu=PosDly_RslvOffsetComp}
            {data-filter={data-filter-type=ALWAYS, max=1, min=0, offset=0}, i-signal-in-i-pdu=PosDly_Enable}
            {data-filter={data-filter-type=ALWAYS, max=1, min=0, offset=0}, i-signal-in-i-pdu=PosDly_IdentFail_Flag}
            {data-filter={data-filter-type=ALWAYS, max=1, min=0, offset=0}, i-signal-in-i-pdu=PosDly_IdentFinish_Flag}
            {data-filter={data-filter-type=ALWAYS, max=1, min=0, offset=0}, i-signal-in-i-pdu=PosDly_Write_Flag}
            {data-filter={data-filter-type=ALWAYS, max=1, min=0, offset=0}, i-signal-in-i-pdu=PosDly_FauPro_Chk_DlyTime_OVal}
            {data-filter={data-filter-type=ALWAYS, max=1, min=0, offset=0}, i-signal-in-i-pdu=PosDly_FauPro_Chk_RslvOfst_OVal}
            {data-filter={data-filter-type=ALWAYS, max=1, min=0, offset=0}, i-signal-in-i-pdu=PosDly_FauPro_Check_Divergence}
            {data-filter={data-filter-type=ALWAYS, max=1, min=0, offset=0}, i-signal-in-i-pdu=PosDly_FauPro_SpdUp_OTm_Flag}
            {data-filter={data-filter-type=ALWAYS, max=6, min=0, offset=0}, i-signal-in-i-pdu=PosDly_Stage}
            {data-filter={data-filter-type=ALWAYS, max=10, min=0, offset=0}, i-signal-in-i-pdu=IMParaIdent_ParEstMainStep}
            {data-filter={data-filter-type=NEW-IS-WITHIN, max=1000, min=0, offset=0}, i-signal-in-i-pdu=IMParaIdent_Rs}
            {data-filter={data-filter-type=NEW-IS-WITHIN, max=1000, min=0, offset=0}, i-signal-in-i-pdu=IMParaIdent_Rr}
            {data-filter={data-filter-type=NEW-IS-WITHIN, max=10000, min=0, offset=0}, i-signal-in-i-pdu=IMParaIdent_Ll}
            {data-filter={data-filter-type=NEW-IS-WITHIN, max=10000, min=0, offset=0}, i-signal-in-i-pdu=IMParaIdent_Lm}
            {data-filter={data-filter-type=NEW-IS-WITHIN, max=10000, min=0, offset=0}, i-signal-in-i-pdu=IMParaIdent_TotalLo}
            {data-filter={data-filter-type=ALWAYS, max=30, min=0, offset=0}, i-signal-in-i-pdu=IMParaIdent_IdentSubStep}
            {data-filter={data-filter-type=NEW-IS-WITHIN, max=4048, min=48}, i-signal-in-i-pdu=MCUMR_EddyCur_Para_Cos_m}
            {data-filter={data-filter-type=ALWAYS, max=5, min=0, offset=0}, i-signal-in-i-pdu=MCUMR_EddyCur_Stage}
            {data-filter={data-filter-type=ALWAYS, max=1, min=0, offset=0}, i-signal-in-i-pdu=MCUMR_EddyCur_IdenFinish_Flag}
            {data-filter={data-filter-type=NEW-IS-WITHIN, max=4048, min=48}, i-signal-in-i-pdu=MCUMR_EddyCur_Para_Sin_m}
            {data-filter={data-filter-type=ALWAYS, max=1, min=0, offset=0}, i-signal-in-i-pdu=MCUMR_EddyCur_Write_Flag}
            {data-filter={data-filter-type=ALWAYS, max=1, min=0, offset=0}, i-signal-in-i-pdu=MCUMR_EddyCur_FauPro_IDEL_OTime_Flag}
            {data-filter={data-filter-type=ALWAYS, max=1, min=0, offset=0}, i-signal-in-i-pdu=MCUMR_EddyCur_FauPro_SpdInstab_Flag}
            {data-filter={data-filter-type=ALWAYS, max=1, min=0, offset=0}, i-signal-in-i-pdu=MCUMR_EddyCur_FauPro_IDPara_OVal_Flag}
            {data-filter={data-filter-type=NEW-IS-WITHIN, max=30000, min=0, offset=0}, i-signal-in-i-pdu=MCUMR_EddyCur_Para_Cos_k}
            {data-filter={data-filter-type=ALWAYS, max=1, min=0, offset=0}, i-signal-in-i-pdu=MCUMR_EddyCur_Enable}
            {data-filter={data-filter-type=NEW-IS-WITHIN, max=30000, min=0, offset=0}, i-signal-in-i-pdu=MCUMR_EddyCur_Para_Sin_k}
            {data-filter={data-filter-type=ALWAYS, max=1, min=0, offset=0}, i-signal-in-i-pdu=MCUMR_EddyCur_IdenFail_Flag}
            {data-filter={data-filter-type=NEW-IS-WITHIN, max=40000, min=0}, i-signal-in-i-pdu=MCUMR_EddyCur_Para_Cos_Pha}
            {data-filter={data-filter-type=NEW-IS-WITHIN, max=40000, min=0}, i-signal-in-i-pdu=MCUMR_EddyCur_Para_Sin_Pha}
            {data-filter={data-filter-type=ALWAYS, max=1, min=0, offset=0}, i-signal-in-i-pdu=MCUMR_EddyCur_ReadSuccess_Flag}
            {data-filter={data-filter-type=ALWAYS, max=1, min=0, offset=0}, i-signal-in-i-pdu=MCUMR_OfsIden_ReadSuccess_Flag}
            {data-filter={data-filter-type=ALWAYS, max=1, min=0, offset=0}, i-signal-in-i-pdu=MCUMR_OfsIden_SpdUp_Overtime}
            {data-filter={data-filter-type=ALWAYS, max=1, min=0, offset=0}, i-signal-in-i-pdu=MCUMR_OfsIden_SpdUp_OverSpd}
            {data-filter={data-filter-type=ALWAYS, max=1, min=0, offset=0}, i-signal-in-i-pdu=MCUMR_OfsIden_IdenDiverge}
            {data-filter={data-filter-type=ALWAYS, max=1, min=0, offset=0}, i-signal-in-i-pdu=MCUMR_OfsIden_IdenCntOver}
            {data-filter={data-filter-type=ALWAYS, max=1, min=0, offset=0}, i-signal-in-i-pdu=MCUMR_OfsIden_MtrLock}
            {data-filter={data-filter-type=NEW-IS-WITHIN, max=3600, min=0, offset=0}, i-signal-in-i-pdu=MCUMR_OfsIden_OfsRslt}
            {data-filter={data-filter-type=ALWAYS, max=7, min=0, offset=0}, i-signal-in-i-pdu=MCUMR_OfsIden_Sts}
            {data-filter={data-filter-type=ALWAYS, max=1, min=0, offset=0}, i-signal-in-i-pdu=MCUMR_OfsIden_Finish}
            {data-filter={data-filter-type=ALWAYS, max=1, min=0, offset=0}, i-signal-in-i-pdu=MCUMR_OfsIden_OfsWrite_Finish}
            {data-filter={data-filter-type=ALWAYS, max=1, min=0, offset=0}, i-signal-in-i-pdu=MCUMR_OfsIden_DirWrite_Finish}
            {data-filter={data-filter-type=ALWAYS, max=2, min=0}, i-signal-in-i-pdu=MCUMR_OfsIden_DirIden_Rslt}
            {data-filter={data-filter-type=ALWAYS, max=1, min=0, offset=0}, i-signal-in-i-pdu=MCUMR_OfsIden_ZeroAlign_OverTime}
            {data-filter={data-filter-type=ALWAYS, max=1, min=0, offset=0}, i-signal-in-i-pdu=MCUMR_OfsIden_ZeroAlign_Fail}
            {data-filter={data-filter-type=ALWAYS, max=1, min=0, offset=0}, i-signal-in-i-pdu=MCUMR_OfsIden_IFStart_Overtime}
            {data-filter={data-filter-type=ALWAYS, max=1, min=0, offset=0}, i-signal-in-i-pdu=MCUMR_OfsIden_IFStart_Fail}
          signal EddyCur_Para_Cos_m: start 0, 12 bit, little-endian, init-value=0, base-type=uint16, implementation-data-type=DT_EddyCur_Para_Cos_m, update-indication-bit-position=-1
          signal EddyCur_Stage: start 12, 3 bit, little-endian, init-value=0, base-type=uint8, implementation-data-type=DT_EddyCur_Stage, update-indication-bit-position=-1
          signal EddyCur_IdenFinish_Flag: start 15, 1 bit, little-endian, init-value=0, base-type=uint8, implementation-data-type=DT_EddyCur_IdenFinish_Flag, update-indication-bit-position=-1
          signal EddyCur_Para_Sin_m: start 16, 12 bit, little-endian, init-value=0, base-type=uint16, implementation-data-type=DT_EddyCur_Para_Sin_m, update-indication-bit-position=-1
          signal EddyCur_Write_Flag: start 28, 1 bit, little-endian, init-value=0, base-type=uint8, implementation-data-type=DT_EddyCur_Write_Flag, update-indication-bit-position=-1
          signal EddyCur_FauPro_IDEL_OTime_Flag: start 29, 1 bit, little-endian, init-value=0, base-type=uint8, implementation-data-type=DT_EddyCur_FauPro_IDEL_OTime_Flag, update-indication-bit-position=-1
          signal EddyCur_FauPro_SpdInstab_Flag: start 30, 1 bit, little-endian, init-value=0, base-type=uint8, implementation-data-type=DT_EddyCur_FauPro_SpdInstab_Flag, update-indication-bit-position=-1
          signal EddyCur_FauPro_IDPara_OVal_Flag: start 31, 1 bit, little-endian, init-value=0, base-type=uint8, implementation-data-type=DT_EddyCur_FauPro_IDPara_OVal_Flag, update-indication-bit-position=-1
          signal EddyCur_Para_Cos_k: start 32, 15 bit, little-endian, init-value=0, base-type=uint16, implementation-data-type=DT_EddyCur_Para_Cos_k, update-indication-bit-position=-1
          signal EddyCur_Enable: start 47, 1 bit, little-endian, init-value=0, base-type=uint8, implementation-data-type=DT_EddyCur_Enable, update-indication-bit-position=-1
          signal EddyCur_Para_Sin_k: start 48, 15 bit, little-endian, init-value=0, base-type=uint16, implementation-data-type=DT_EddyCur_Para_Sin_k, update-indication-bit-position=-1
          signal EddyCur_IdenFail_Flag: start 63, 1 bit, little-endian, init-value=0, base-type=uint8, implementation-data-type=DT_EddyCur_IdenFail_Flag, update-indication-bit-position=-1
          signal EddyCur_Para_Cos_Pha: start 64, 16 bit, little-endian, init-value=0, base-type=uint16, implementation-data-type=DT_EddyCur_Para_Cos_Pha, update-indication-bit-position=-1
          signal EddyCur_Para_Sin_Pha: start 80, 16 bit, little-endian, init-value=0, base-type=uint16, implementation-data-type=DT_EddyCur_Para_Sin_Pha, update-indication-bit-position=-1
          signal EddyCur_ReadSuccess_Flag: start 96, 1 bit, little-endian, init-value=0, base-type=uint8, implementation-data-type=DT_EddyCur_ReadSuccess_Flag, update-indication-bit-position=-1
          signal OfsIden_ReadSuccess_Flag: start 98, 1 bit, little-endian, init-value=0, base-type=uint8, implementation-data-type=DT_OfsIden_ReadSuccess_Flag, update-indication-bit-position=-1
          signal OfsIden_SpdUp_Overtime: start 99, 1 bit, little-endian, init-value=0, base-type=uint8, implementation-data-type=DT_OfsIden_SpdUp_Overtime, update-indication-bit-position=-1
          signal OfsIden_SpdUp_OverSpd: start 100, 1 bit, little-endian, init-value=0, base-type=uint8, implementation-data-type=DT_OfsIden_SpdUp_OverSpd, update-indication-bit-position=-1
          signal OfsIden_IdenDiverge: start 101, 1 bit, little-endian, init-value=0, base-type=uint8, implementation-data-type=DT_OfsIden_IdenDiverge, update-indication-bit-position=-1
          signal OfsIden_IdenCntOver: start 102, 1 bit, little-endian, init-value=0, base-type=uint8, implementation-data-type=DT_OfsIden_IdenCntOver, update-indication-bit-position=-1
          signal OfsIden_MtrLock: start 103, 1 bit, little-endian, init-value=0, base-type=uint8, implementation-data-type=DT_OfsIden_MtrLock, update-indication-bit-position=-1
          signal OfsIden_OfsRslt: start 104, 12 bit, little-endian, init-value=0, base-type=uint16, implementation-data-type=DT_OfsIden_OfsRslt, update-indication-bit-position=-1
          signal OfsIden_Sts: start 116, 3 bit, little-endian, init-value=0, base-type=uint8, implementation-data-type=DT_OfsIden_Sts, update-indication-bit-position=-1
          signal OfsIden_Finish: start 119, 1 bit, little-endian, init-value=0, base-type=uint8, implementation-data-type=DT_OfsIden_Finish, update-indication-bit-position=-1
          signal OfsIden_OfsWrite_Finish: start 120, 1 bit, little-endian, init-value=0, base-type=uint8, implementation-data-type=DT_OfsIden_OfsWrite_Finish, update-indication-bit-position=-1
          signal OfsIden_DirWrite_Finish: start 121, 1 bit, little-endian, init-value=0, base-type=uint8, implementation-data-type=DT_OfsIden_DirWrite_Finish, update-indication-bit-position=-1
          signal OfsIden_DirIden_Rslt: start 122, 2 bit, little-endian, init-value=0, base-type=uint8, implementation-data-type=DT_OfsIden_DirIden_Rslt, update-indication-bit-position=-1
          signal OfsIden_ZeroAlign_OverTime: start 124, 1 bit, little-endian, init-value=0, base-type=uint8, implementation-data-type=DT_OfsIden_ZeroAlign_OverTime, update-indication-bit-position=-1
          signal OfsIden_ZeroAlign_Fail: start 125, 1 bit, little-endian, init-value=0, base-type=uint8, implementation-data-type=DT_OfsIden_ZeroAlign_Fail, update-indication-bit-position=-1
          signal OfsIden_IFStart_Overtime: start 126, 1 bit, little-endian, init-value=0, base-type=uint8, implementation-data-type=DT_OfsIden_IFStart_Overtime, update-indication-bit-position=-1
          signal OfsIden_IFStart_Fail: start 127, 1 bit, little-endian, init-value=0, base-type=uint8, implementation-data-type=DT_OfsIden_IFStart_Fail, update-indication-bit-position=-1
          signal PosDly_Cal_RslvDelayTime: start 128, 16 bit, little-endian, init-value=0, base-type=uint16, implementation-data-type=DT_PosDly_Cal_RslvDelayTime, update-indication-bit-position=-1
          signal PosDly_Theta_k_Std: start 144, 15 bit, little-endian, init-value=0, base-type=uint16, implementation-data-type=DT_PosDly_Theta_k_Std, update-indication-bit-position=-1
          signal PosDly_Supplier: start 159, 1 bit, little-endian, init-value=0, base-type=uint8, implementation-data-type=DT_PosDly_Supplier, update-indication-bit-position=-1
          signal PosDly_FauPro_Ident_OTm_Flag: start 160, 1 bit, little-endian, init-value=0, base-type=uint8, implementation-data-type=DT_PosDly_FauPro_Ident_OTm_Flag, update-indication-bit-position=-1
          signal PosDly_FauPro_SpdDn_OTm_Flag: start 161, 1 bit, little-endian, init-value=0, base-type=uint8, implementation-data-type=DT_PosDly_FauPro_SpdDn_OTm_Flag, update-indication-bit-position=-1
          signal PosDly_RslvOffsetComp: start 162, 6 bit, little-endian, init-value=0, base-type=uint8, implementation-data-type=DT_PosDly_RslvOffsetComp, update-indication-bit-position=-1
          signal PosDly_Enable: start 168, 1 bit, little-endian, init-value=0, base-type=uint8, implementation-data-type=DT_PosDly_Enable, update-indication-bit-position=-1
          signal PosDly_IdentFail_Flag: start 169, 1 bit, little-endian, init-value=0, base-type=uint8, implementation-data-type=DT_PosDly_IdentFail_Flag, update-indication-bit-position=-1
          signal PosDly_IdentFinish_Flag: start 170, 1 bit, little-endian, init-value=0, base-type=uint8, implementation-data-type=DT_PosDly_IdentFinish_Flag, update-indication-bit-position=-1
          signal PosDly_Write_Flag: start 171, 1 bit, little-endian, init-value=0, base-type=uint8, implementation-data-type=DT_PosDly_Write_Flag, update-indication-bit-position=-1
          signal PosDly_FauPro_Chk_DlyTime_OVal: start 172, 1 bit, little-endian, init-value=0, base-type=uint8, implementation-data-type=DT_PosDly_FauPro_Chk_DlyTime_OVal, update-indication-bit-position=-1
          signal PosDly_FauPro_Chk_RslvOfst_OVal: start 173, 1 bit, little-endian, init-value=0, base-type=uint8, implementation-data-type=DT_PosDly_FauPro_Chk_RslvOfst_OVal, update-indication-bit-position=-1
          signal PosDly_FauPro_Check_Divergence: start 174, 1 bit, little-endian, init-value=0, base-type=uint8, implementation-data-type=DT_PosDly_FauPro_Check_Divergence, update-indication-bit-position=-1
          signal PosDly_FauPro_SpdUp_OTm_Flag: start 175, 1 bit, little-endian, init-value=0, base-type=uint8, implementation-data-type=DT_PosDly_FauPro_SpdUp_OTm_Flag, update-indication-bit-position=-1
          signal PosDly_Stage: start 176, 3 bit, little-endian, init-value=0, base-type=uint8, implementation-data-type=DT_PosDly_Stage, update-indication-bit-position=-1
          signal IMParaIdent_ParEstMainStep: start 179, 4 bit, little-endian, init-value=0, base-type=uint8, implementation-data-type=DT_IMParaIdent_ParEstMainStep, update-indication-bit-position=-1
          signal IMParaIdent_Rs: start 183, 10 bit, little-endian, init-value=0, base-type=uint16, implementation-data-type=DT_IMParaIdent_Rs, update-indication-bit-position=-1
          signal IMParaIdent_Rr: start 193, 10 bit, little-endian, init-value=0, base-type=uint16, implementation-data-type=DT_IMParaIdent_Rr, update-indication-bit-position=-1
          signal IMParaIdent_Ll: start 203, 14 bit, little-endian, init-value=0, base-type=uint16, implementation-data-type=DT_IMParaIdent_Ll, update-indication-bit-position=-1
          signal IMParaIdent_Lm: start 217, 14 bit, little-endian, init-value=0, base-type=uint16, implementation-data-type=DT_IMParaIdent_Lm, update-indication-bit-position=-1
          signal IMParaIdent_TotalLo: start 231, 14 bit, little-endian, init-value=0, base-type=uint16, implementation-data-type=DT_IMParaIdent_TotalLo, update-indication-bit-position=-1
          signal IMParaIdent_IdentSubStep: start 245, 5 bit, little-endian, init-value=0, base-type=uint8, implementation-data-type=DT_IMParaIdent_IdentSubStep, update-indication-bit-position=-1
          signal MCUMR_EddyCur_Para_Cos_m: start 256, 12 bit, little-endian, init-value=0, base-type=uint16, implementation-data-type=DT_MCUMR_EddyCur_Para_Cos_m, update-indication-bit-position=-1
          signal MCUMR_EddyCur_Stage: start 268, 3 bit, little-endian, init-value=0, base-type=uint8, implementation-data-type=DT_MCUMR_EddyCur_Stage, update-indication-bit-position=-1
          signal MCUMR_EddyCur_IdenFinish_Flag: start 271, 1 bit, little-endian, init-value=0, base-type=uint8, implementation-data-type=DT_MCUMR_EddyCur_IdenFinish_Flag, update-indication-bit-position=-1
          signal MCUMR_EddyCur_Para_Sin_m: start 272, 12 bit, little-endian, init-value=0, base-type=uint16, implementation-data-type=DT_MCUMR_EddyCur_Para_Sin_m, update-indication-bit-position=-1
          signal MCUMR_EddyCur_Write_Flag: start 284, 1 bit, little-endian, init-value=0, base-type=uint8, implementation-data-type=DT_MCUMR_EddyCur_Write_Flag, update-indication-bit-position=-1
          signal MCUMR_EddyCur_FauPro_IDEL_OTime_Flag: start 285, 1 bit, little-endian, init-value=0, base-type=uint8, implementation-data-type=DT_MCUMR_EddyCur_FauPro_IDEL_OTime_Flag, update-indication-bit-position=-1
          signal MCUMR_EddyCur_FauPro_SpdInstab_Flag: start 286, 1 bit, little-endian, init-value=0, base-type=uint8, implementation-data-type=DT_MCUMR_EddyCur_FauPro_SpdInstab_Flag, update-indication-bit-position=-1
          signal MCUMR_EddyCur_FauPro_IDPara_OVal_Flag: start 287, 1 bit, little-endian, init-value=0, base-type=uint8, implementation-data-type=DT_MCUMR_EddyCur_FauPro_IDPara_OVal_Flag, update-indication-bit-position=-1
          signal MCUMR_EddyCur_Para_Cos_k: start 288, 15 bit, little-endian, init-value=0, base-type=uint16, implementation-data-type=DT_MCUMR_EddyCur_Para_Cos_k, update-indication-bit-position=-1
          signal MCUMR_EddyCur_Enable: start 303, 1 bit, little-endian, init-value=0, base-type=uint8, implementation-data-type=DT_MCUMR_EddyCur_Enable, update-indication-bit-position=-1
          signal MCUMR_EddyCur_Para_Sin_k: start 304, 15 bit, little-endian, init-value=0, base-type=uint16, implementation-data-type=DT_MCUMR_EddyCur_Para_Sin_k, update-indication-bit-position=-1
          signal MCUMR_EddyCur_IdenFail_Flag: start 319, 1 bit, little-endian, init-value=0, base-type=uint8, implementation-data-type=DT_MCUMR_EddyCur_IdenFail_Flag, update-indication-bit-position=-1
          signal MCUMR_EddyCur_Para_Cos_Pha: start 320, 16 bit, little-endian, init-value=0, base-type=uint16, implementation-data-type=DT_MCUMR_EddyCur_Para_Cos_Pha, update-indication-bit-position=-1
          signal MCUMR_EddyCur_Para_Sin_Pha: start 336, 16 bit, little-endian, init-value=0, base-type=uint16, implementation-data-type=DT_MCUMR_EddyCur_Para_Sin_Pha, update-indication-bit-position=-1
          signal MCUMR_EddyCur_ReadSuccess_Flag: start 352, 1 bit, little-endian, init-value=0, base-type=uint8, implementation-data-type=DT_MCUMR_EddyCur_ReadSuccess_Flag, update-indication-bit-position=-1
          signal MCUMR_OfsIden_ReadSuccess_Flag: start 353, 1 bit, little-endian, init-value=0, base-type=uint8, implementation-data-type=DT_MCUMR_OfsIden_ReadSuccess_Flag, update-indication-bit-position=-1
          signal MCUMR_OfsIden_SpdUp_Overtime: start 354, 1 bit, little-endian, init-value=0, base-type=uint8, implementation-data-type=DT_MCUMR_OfsIden_SpdUp_Overtime, update-indication-bit-position=-1
          signal MCUMR_OfsIden_SpdUp_OverSpd: start 355, 1 bit, little-endian, init-value=0, base-type=uint8, implementation-data-type=DT_MCUMR_OfsIden_SpdUp_OverSpd, update-indication-bit-position=-1
          signal MCUMR_OfsIden_IdenDiverge: start 356, 1 bit, little-endian, init-value=0, base-type=uint8, implementation-data-type=DT_MCUMR_OfsIden_IdenDiverge, update-indication-bit-position=-1
          signal MCUMR_OfsIden_IdenCntOver: start 357, 1 bit, little-endian, init-value=0, base-type=uint8, implementation-data-type=DT_MCUMR_OfsIden_IdenCntOver, update-indication-bit-position=-1
          signal MCUMR_OfsIden_MtrLock: start 358, 1 bit, little-endian, init-value=0, base-type=uint8, implementation-data-type=DT_MCUMR_OfsIden_MtrLock, update-indication-bit-position=-1
          signal MCUMR_OfsIden_OfsRslt: start 359, 12 bit, little-endian, init-value=0, base-type=uint16, implementation-data-type=DT_MCUMR_OfsIden_OfsRslt, update-indication-bit-position=-1
          signal MCUMR_OfsIden_Sts: start 371, 3 bit, little-endian, init-value=0, base-type=uint8, implementation-data-type=DT_MCUMR_OfsIden_Sts, update-indication-bit-position=-1
          signal MCUMR_OfsIden_Finish: start 374, 1 bit, little-endian, init-value=0, base-type=uint8, implementation-data-type=DT_MCUMR_OfsIden_Finish, update-indication-bit-position=-1
          signal MCUMR_OfsIden_OfsWrite_Finish: start 375, 1 bit, little-endian, init-value=0, base-type=uint8, implementation-data-type=DT_MCUMR_OfsIden_OfsWrite_Finish, update-indication-bit-position=-1
          signal MCUMR_OfsIden_DirWrite_Finish: start 376, 1 bit, little-endian, init-value=0, base-type=uint8, implementation-data-type=DT_MCUMR_OfsIden_DirWrite_Finish, update-indication-bit-position=-1
          signal MCUMR_OfsIden_DirIden_Rslt: start 377, 2 bit, little-endian, init-value=0, base-type=uint8, implementation-data-type=DT_MCUMR_OfsIden_DirIden_Rslt, update-indication-bit-position=-1
          signal MCUMR_OfsIden_ZeroAlign_OverTime: start 379, 1 bit, little-endian, init-value=0, base-type=uint8, implementation-data-type=DT_MCUMR_OfsIden_ZeroAlign_OverTime, update-indication-bit-position=-1
          signal MCUMR_OfsIden_ZeroAlign_Fail: start 380, 1 bit, little-endian, init-value=0, base-type=uint8, implementation-data-type=DT_MCUMR_OfsIden_ZeroAlign_Fail, update-indication-bit-position=-1
          signal MCUMR_OfsIden_IFStart_Overtime: start 381, 1 bit, little-endian, init-value=0, base-type=uint8, implementation-data-type=DT_MCUMR_OfsIden_IFStart_Overtime, update-indication-bit-position=-1
          signal MCUMR_OfsIden_IFStart_Fail: start 382, 1 bit, little-endian, init-value=0, base-type=uint8, implementation-data-type=DT_MCUMR_OfsIden_IFStart_Fail, update-indication-bit-position=-1
      frame MCU_0x5C9: id 0x5C9, from MVCU, frame-length=32, can-addressing-mode=STANDARD, can-fd-frame-support=true, can-frame-tx-behavior=CAN-FD
        carries pdu MCU_0x5C9: packing-byte-order=little-endian, start-position=0, update-indication-bit-position=-1
        pdu MCU_0x5C9: length=32, transmission-mode-false-timing=cyclic-timing={time-offset=0.0, time-period=0.01}, transmission-mode-true-timing=cyclic-timing={time-offset=0.0, time-period=0.01}
          transmission-mode-conditions:
            {data-filter={data-filter-type=NEW-IS-WITHIN, max=5000, min=0, offset=0}, i-signal-in-i-pdu=DelayIden_Rslt_Avg}
            {data-filter={data-filter-type=ALWAYS, max=1, min=0, offset=0}, i-signal-in-i-pdu=DelayIden_OverRange}
            {data-filter={data-filter-type=ALWAYS, max=1, min=0, offset=0}, i-signal-in-i-pdu=DelayIden_Iden_Finish}
            {data-filter={data-filter-type=ALWAYS, max=1, min=0, offset=0}, i-signal-in-i-pdu=DelayIden_Write_Finish}
            {data-filter={data-filter-type=NEW-IS-WITHIN, max=5000, min=0, offset=0}, i-signal-in-i-pdu=DelayIden_Rslt_U}
            {data-filter={data-filter-type=NEW-IS-WITHIN, max=5000, min=0, offset=0}, i-signal-in-i-pdu=DelayIden_Rslt_V}
            {data-filter={data-filter-type=NEW-IS-WITHIN, max=5000, min=0, offset=0}, i-signal-in-i-pdu=DelayIden_Rslt_W}
            {data-filter={data-filter-type=NEW-IS-WITHIN, max=10000, min=0, offset=0}, i-signal-in-i-pdu=GainIden_Is_Samp_U}
            {data-filter={data-filter-type=NEW-IS-WITHIN, max=500, min=0, offset=1}, i-signal-in-i-pdu=GainIden_Rslt_U}
            {data-filter={data-filter-type=ALWAYS, max=1, min=0, offset=0}, i-signal-in-i-pdu=GainIden_OverRange}
            {data-filter={data-filter-type=NEW-IS-WITHIN, max=10000, min=0, offset=0}, i-signal-in-i-pdu=GainIden_Is_Samp_V}
            {data-filter={data-filter-type=NEW-IS-WITHIN, max=500, min=0, offset=1}, i-signal-in-i-pdu=GainIden_Rslt_V}
            {data-filter={data-filter-type=ALWAYS, max=1, min=0, offset=0}, i-signal-in-i-pdu=GainIden_Iden_Finish}
            {data-filter={data-filter-type=NEW-IS-WITHIN, max=10000, min=0, offset=0}, i-signal-in-i-pdu=GainIden_Is_Samp_W}
            {data-filter={data-filter-type=NEW-IS-WITHIN, max=500, min=0, offset=1}, i-signal-in-i-pdu=GainIden_Rslt_W}
            {data-filter={data-filter-type=ALWAYS, max=1, min=0, offset=0}, i-signal-in-i-pdu=GainIden_Write_Finish}
            {data-filter={data-filter-type=NEW-IS-WITHIN, max=2000, min=0}, i-signal-in-i-pdu=GainIden_Curr_Peak_U}
            {data-filter={data-filter-type=NEW-IS-WITHIN, max=2000, min=0}, i-signal-in-i-pdu=GainIden_Curr_Peak_V}
            {data-filter={data-filter-type=NEW-IS-WITHIN, max=2000, min=0}, i-signal-in-i-pdu=GainIden_Curr_Peak_W}
            {data-filter={data-filter-type=NEW-IS-WITHIN, max=4095, min=0}, i-signal-in-i-pdu=CurrLoad_CurExt_U}
            {data-filter={data-filter-type=NEW-IS-WITHIN, max=4095, min=0}, i-signal-in-i-pdu=CurrLoad_CurExt_V}
            {data-filter={data-filter-type=NEW-IS-WITHIN, max=4095, min=0}, i-signal-in-i-pdu=CurrLoad_CurExt_W}
            {data-filter={data-filter-type=NEW-IS-WITHIN, max=4095, min=0, offset=0}, i-signal-in-i-pdu=CurrLoad_offset_Iu}
            {data-filter={data-filter-type=NEW-IS-WITHIN, max=4095, min=0, offset=0}, i-signal-in-i-pdu=CurrLoad_offset_Iv}
            {data-filter={data-filter-type=NEW-IS-WITHIN, max=4095, min=0, offset=0}, i-signal-in-i-pdu=CurrLoad_offset_Iw}
            {data-filter={data-filter-type=NEW-IS-WITHIN, max=5000, min=0, offset=0}, i-signal-in-i-pdu=MCUMR_DelayIden_Rslt_Avg}
            {data-filter={data-filter-type=ALWAYS, max=1, min=0, offset=0}, i-signal-in-i-pdu=MCUMR_DelayIden_OverRange}
            {data-filter={data-filter-type=ALWAYS, max=1, min=0, offset=0}, i-signal-in-i-pdu=MCUMR_DelayIden_Iden_Finish}
            {data-filter={data-filter-type=ALWAYS, max=1, min=0, offset=0}, i-signal-in-i-pdu=MCUMR_DelayIden_Write_Finish}
            {data-filter={data-filter-type=NEW-IS-WITHIN, max=5000, min=0, offset=0}, i-signal-in-i-pdu=MCUMR_DelayIden_Rslt_U}
            {data-filter={data-filter-type=NEW-IS-WITHIN, max=5000, min=0, offset=0}, i-signal-in-i-pdu=MCUMR_DelayIden_Rslt_V}
            {data-filter={data-filter-type=NEW-IS-WITHIN, max=5000, min=0, offset=0}, i-signal-in-i-pdu=MCUMR_DelayIden_Rslt_W}
            {data-filter={data-filter-type=NEW-IS-WITHIN, max=10000, min=0, offset=0}, i-signal-in-i-pdu=MCUMR_GainIden_Is_Samp_U}
            {data-filter={data-filter-type=NEW-IS-WITHIN, max=500, min=0, offset=1}, i-signal-in-i-pdu=MCUMR_GainIden_Rslt_U}
            {data-filter={data-filter-type=ALWAYS, max=1, min=0, offset=0}, i-signal-in-i-pdu=MCUMR_GainIden_OverRange}
            {data-filter={data-filter-type=NEW-IS-WITHIN, max=10000, min=0, offset=0}, i-signal-in-i-pdu=MCUMR_GainIden_Is_Samp_V}
            {data-filter={data-filter-type=NEW-IS-WITHIN, max=500, min=0, offset=1}, i-signal-in-i-pdu=MCUMR_GainIden_Rslt_V}
            {data-filter={data-filter-type=ALWAYS, max=1, min=0, offset=0}, i-signal-in-i-pdu=MCUMR_GainIden_Iden_Finish}
            {data-filter={data-filter-type=NEW-IS-WITHIN, max=10000, min=0, offset=0}, i-signal-in-i-pdu=MCUMR_GainIden_Is_Samp_W}
            {data-filter={data-filter-type=NEW-IS-WITHIN, max=500, min=0, offset=1}, i-signal-in-i-pdu=MCUMR_GainIden_Rslt_W}
            {data-filter={data-filter-type=ALWAYS, max=1, min=0, offset=0}, i-signal-in-i-pdu=MCUMR_GainIden_Write_Finish}
            {data-filter={data-filter-type=NEW-IS-WITHIN, max=2000, min=0}, i-signal-in-i-pdu=MCUMR_GainIden_Curr_Peak_U}
            {data-filter={data-filter-type=NEW-IS-WITHIN, max=2000, min=0}, i-signal-in-i-pdu=MCUMR_GainIden_Curr_Peak_V}
            {data-filter={data-filter-type=NEW-IS-WITHIN, max=2000, min=0}, i-signal-in-i-pdu=MCUMR_GainIden_Curr_Peak_W}
            {data-filter={data-filter-type=NEW-IS-WITHIN, max=4095, min=0}, i-signal-in-i-pdu=MCUMR_CurrLoad_CurExt_U}
            {data-filter={data-filter-type=NEW-IS-WITHIN, max=4095, min=0}, i-signal-in-i-pdu=MCUMR_CurrLoad_CurExt_V}
            {data-filter={data-filter-type=NEW-IS-WITHIN, max=4095, min=0}, i-signal-in-i-pdu=MCUMR_CurrLoad_CurExt_W}
            {data-filter={data-filter-type=NEW-IS-WITHIN, max=4095, min=0, offset=0}, i-signal-in-i-pdu=MCUMR_CurrLoad_offset_Iu}
            {data-filter={data-filter-type=NEW-IS-WITHIN, max=4095, min=0, offset=0}, i-signal-in-i-pdu=MCUMR_CurrLoad_offset_Iv}
            {data-filter={data-filter-type=NEW-IS-WITHIN, max=4095, min=0, offset=0}, i-signal-in-i-pdu=MCUMR_CurrLoad_offset_Iw}
          signal DelayIden_Rslt_Avg: start 0, 13 bit, little-endian, init-value=0, base-type=uint16, implementation-data-type=DT_DelayIden_Rslt_Avg, update-indication-bit-position=-1
          signal DelayIden_OverRange: start 13, 1 bit, little-endian, init-value=0, base-type=uint8, implementation-data-type=DT_DelayIden_OverRange, update-indication-bit-position=-1
          signal DelayIden_Iden_Finish: start 14, 1 bit, little-endian, init-value=0, base-type=uint8, implementation-data-type=DT_DelayIden_Iden_Finish, update-indication-bit-position=-1
          signal DelayIden_Write_Finish: start 15, 1 bit, little-endian, init-value=0, base-type=uint8, implementation-data-type=DT_DelayIden_Write_Finish, update-indication-bit-position=-1
          signal DelayIden_Rslt_U: start 16, 13 bit, little-endian, init-value=0, base-type=uint16, implementation-data-type=DT_DelayIden_Rslt_U, update-indication-bit-position=-1
          signal DelayIden_Rslt_V: start 29, 13 bit, little-endian, init-value=0, base-type=uint16, implementation-data-type=DT_DelayIden_Rslt_V, update-indication-bit-position=-1
          signal DelayIden_Rslt_W: start 42, 13 bit, little-endian, init-value=0, base-type=uint16, implementation-data-type=DT_DelayIden_Rslt_W, update-indication-bit-position=-1
          signal GainIden_Is_Samp_U: start 56, 14 bit, little-endian, init-value=0, base-type=uint16, implementation-data-type=DT_GainIden_Is_Samp_U, update-indication-bit-position=-1
          signal GainIden_Rslt_U: start 70, 9 bit, little-endian, init-value=0, base-type=uint16, implementation-data-type=DT_GainIden_Rslt_U, update-indication-bit-position=-1
          signal GainIden_OverRange: start 79, 1 bit, little-endian, init-value=0, base-type=uint8, implementation-data-type=DT_GainIden_OverRange, update-indication-bit-position=-1
          signal GainIden_Is_Samp_V: start 80, 14 bit, little-endian, init-value=0, base-type=uint16, implementation-data-type=DT_GainIden_Is_Samp_V, update-indication-bit-position=-1
          signal GainIden_Rslt_V: start 94, 9 bit, little-endian, init-value=0, base-type=uint16, implementation-data-type=DT_GainIden_Rslt_V, update-indication-bit-position=-1
          signal GainIden_Iden_Finish: start 103, 1 bit, little-endian, init-value=0, base-type=uint8, implementation-data-type=DT_GainIden_Iden_Finish, update-indication-bit-position=-1
          signal GainIden_Is_Samp_W: start 104, 14 bit, little-endian, init-value=0, base-type=uint16, implementation-data-type=DT_GainIden_Is_Samp_W, update-indication-bit-position=-1
          signal GainIden_Rslt_W: start 118, 9 bit, little-endian, init-value=0, base-type=uint16, implementation-data-type=DT_GainIden_Rslt_W, update-indication-bit-position=-1
          signal GainIden_Write_Finish: start 127, 1 bit, little-endian, init-value=0, base-type=uint8, implementation-data-type=DT_GainIden_Write_Finish, update-indication-bit-position=-1
          signal GainIden_Curr_Peak_U: start 128, 11 bit, little-endian, init-value=0, base-type=uint16, implementation-data-type=DT_GainIden_Curr_Peak_U, update-indication-bit-position=-1
          signal GainIden_Curr_Peak_V: start 139, 11 bit, little-endian, init-value=0, base-type=uint16, implementation-data-type=DT_GainIden_Curr_Peak_V, update-indication-bit-position=-1
          signal GainIden_Curr_Peak_W: start 150, 11 bit, little-endian, init-value=0, base-type=uint16, implementation-data-type=DT_GainIden_Curr_Peak_W, update-indication-bit-position=-1
          signal CurrLoad_CurExt_U: start 168, 12 bit, little-endian, init-value=0, base-type=uint16, implementation-data-type=DT_CurrLoad_CurExt_U, update-indication-bit-position=-1
          signal CurrLoad_CurExt_V: start 180, 12 bit, little-endian, init-value=0, base-type=uint16, implementation-data-type=DT_CurrLoad_CurExt_V, update-indication-bit-position=-1
          signal CurrLoad_CurExt_W: start 192, 12 bit, little-endian, init-value=0, base-type=uint16, implementation-data-type=DT_CurrLoad_CurExt_W, update-indication-bit-position=-1
          signal CurrLoad_offset_Iu: start 204, 12 bit, little-endian, init-value=0, base-type=uint16, implementation-data-type=DT_CurrLoad_offset_Iu, update-indication-bit-position=-1
          signal CurrLoad_offset_Iv: start 216, 12 bit, little-endian, init-value=0, base-type=uint16, implementation-data-type=DT_CurrLoad_offset_Iv, update-indication-bit-position=-1
          signal CurrLoad_offset_Iw: start 228, 12 bit, little-endian, init-value=0, base-type=uint16, implementation-data-type=DT_CurrLoad_offset_Iw, update-indication-bit-position=-1
          signal MCUMR_DelayIden_Rslt_Avg: start 256, 13 bit, little-endian, init-value=0, base-type=uint16, implementation-data-type=DT_MCUMR_DelayIden_Rslt_Avg, update-indication-bit-position=-1
          signal MCUMR_DelayIden_OverRange: start 269, 1 bit, little-endian, init-value=0, base-type=uint8, implementation-data-type=DT_MCUMR_DelayIden_OverRange, update-indication-bit-position=-1
          signal MCUMR_DelayIden_Iden_Finish: start 270, 1 bit, little-endian, init-value=0, base-type=uint8, implementation-data-type=DT_MCUMR_DelayIden_Iden_Finish, update-indication-bit-position=-1
          signal MCUMR_DelayIden_Write_Finish: start 271, 1 bit, little-endian, init-value=0, base-type=uint8, implementation-data-type=DT_MCUMR_DelayIden_Write_Finish, update-indication-bit-position=-1
          signal MCUMR_DelayIden_Rslt_U: start 272, 13 bit, little-endian, init-value=0, base-type=uint16, implementation-data-type=DT_MCUMR_DelayIden_Rslt_U, update-indication-bit-position=-1
          signal MCUMR_DelayIden_Rslt_V: start 285, 13 bit, little-endian, init-value=0, base-type=uint16, implementation-data-type=DT_MCUMR_DelayIden_Rslt_V, update-indication-bit-position=-1
          signal MCUMR_DelayIden_Rslt_W: start 298, 13 bit, little-endian, init-value=0, base-type=uint16, implementation-data-type=DT_MCUMR_DelayIden_Rslt_W, update-indication-bit-position=-1
          signal MCUMR_GainIden_Is_Samp_U: start 311, 14 bit, little-endian, init-value=0, base-type=uint16, implementation-data-type=DT_MCUMR_GainIden_Is_Samp_U, update-indication-bit-position=-1
          signal MCUMR_GainIden_Rslt_U: start 325, 9 bit, little-endian, init-value=0, base-type=uint16, implementation-data-type=DT_MCUMR_GainIden_Rslt_U, update-indication-bit-position=-1
          signal MCUMR_GainIden_OverRange: start 334, 1 bit, little-endian, init-value=0, base-type=uint8, implementation-data-type=DT_MCUMR_GainIden_OverRange, update-indication-bit-position=-1
          signal MCUMR_GainIden_Is_Samp_V: start 335, 14 bit, little-endian, init-value=0, base-type=uint16, implementation-data-type=DT_MCUMR_GainIden_Is_Samp_V, update-indication-bit-position=-1
          signal MCUMR_GainIden_Rslt_V: start 349, 9 bit, little-endian, init-value=0, base-type=uint16, implementation-data-type=DT_MCUMR_GainIden_Rslt_V, update-indication-bit-position=-1
          signal MCUMR_GainIden_Iden_Finish: start 358, 1 bit, little-endian, init-value=0, base-type=uint8, implementation-data-type=DT_MCUMR_GainIden_Iden_Finish, update-indication-bit-position=-1
          signal MCUMR_GainIden_Is_Samp_W: start 359, 14 bit, little-endian, init-value=0, base-type=uint16, implementation-data-type=DT_MCUMR_GainIden_Is_Samp_W, update-indication-bit-position=-1
          signal MCUMR_GainIden_Rslt_W: start 373, 9 bit, little-endian, init-value=0, base-type=uint16, implementation-data-type=DT_MCUMR_GainIden_Rslt_W, update-indication-bit-position=-1
          signal MCUMR_GainIden_Write_Finish: start 382, 1 bit, little-endian, init-value=0, base-type=uint8, implementation-data-type=DT_MCUMR_GainIden_Write_Finish, update-indication-bit-position=-1
          signal MCUMR_GainIden_Curr_Peak_U: start 383, 11 bit, little-endian, init-value=0, base-type=uint16, implementation-data-type=DT_MCUMR_GainIden_Curr_Peak_U, update-indication-bit-position=-1
          signal MCUMR_GainIden_Curr_Peak_V: start 394, 11 bit, little-endian, init-value=0, base-type=uint16, implementation-data-type=DT_MCUMR_GainIden_Curr_Peak_V, update-indication-bit-position=-1
          signal MCUMR_GainIden_Curr_Peak_W: start 405, 11 bit, little-endian, init-value=0, base-type=uint16, implementation-data-type=DT_MCUMR_GainIden_Curr_Peak_W, update-indication-bit-position=-1
          signal MCUMR_CurrLoad_CurExt_U: start 416, 12 bit, little-endian, init-value=0, base-type=uint16, implementation-data-type=DT_MCUMR_CurrLoad_CurExt_U, update-indication-bit-position=-1
          signal MCUMR_CurrLoad_CurExt_V: start 428, 12 bit, little-endian, init-value=0, base-type=uint16, implementation-data-type=DT_MCUMR_CurrLoad_CurExt_V, update-indication-bit-position=-1
          signal MCUMR_CurrLoad_CurExt_W: start 440, 12 bit, little-endian, init-value=0, base-type=uint16, implementation-data-type=DT_MCUMR_CurrLoad_CurExt_W, update-indication-bit-position=-1
          signal MCUMR_CurrLoad_offset_Iu: start 452, 12 bit, little-endian, init-value=0, base-type=uint16, implementation-data-type=DT_MCUMR_CurrLoad_offset_Iu, update-indication-bit-position=-1
          signal MCUMR_CurrLoad_offset_Iv: start 464, 12 bit, little-endian, init-value=0, base-type=uint16, implementation-data-type=DT_MCUMR_CurrLoad_offset_Iv, update-indication-bit-position=-1
          signal MCUMR_CurrLoad_offset_Iw: start 476, 12 bit, little-endian, init-value=0, base-type=uint16, implementation-data-type=DT_MCUMR_CurrLoad_offset_Iw, update-indication-bit-position=-1
      frame MCU_0x5C8: id 0x5C8, from MVCU, frame-length=16, can-addressing-mode=STANDARD, can-fd-frame-support=true, can-frame-tx-behavior=CAN-FD
        carries pdu MCU_0x5C8: packing-byte-order=little-endian, start-position=0, update-indication-bit-position=-1
        pdu MCU_0x5C8: length=16, transmission-mode-false-timing=cyclic-timing={time-offset=0.0, time-period=0.01}, transmission-mode-true-timing=cyclic-timing={time-offset=0.0, time-period=0.01}
          transmission-mode-conditions:
            {data-filter={data-filter-type=ALWAYS, max=255, min=0}, i-signal-in-i-pdu=Harness_igbt_temp{1..3}}
            {data-filter={data-filter-type=ALWAYS, max=255, min=0}, i-signal-in-i-pdu=Harness_CoolWaterTemp}
            {data-filter={data-filter-type=NEW-IS-WITHIN, max=65535, min=0, offset=0}, i-signal-in-i-pdu=Harness_V_DC}
            {data-filter={data-filter-type=ALWAYS, max=255, min=0, offset=0}, i-signal-in-i-pdu=Harness_PWM_DIR}
            {data-filter={data-filter-type=ALWAYS, max=1, min=0, offset=0}, i-signal-in-i-pdu=Harness_HVIL_State}
            {data-filter={data-filter-type=ALWAYS, max=1, min=0, offset=0}, i-signal-in-i-pdu=Harness_crash_err_flag}
            {data-filter={data-filter-type=ALWAYS, max=1, min=0, offset=0}, i-signal-in-i-pdu=Harness_KeyON}
            {data-filter={data-filter-type=ALWAYS, max=1, min=0, offset=0}, i-signal-in-i-pdu=Harness_HWRdc}
            {data-filter={data-filter-type=ALWAYS, max=1, min=0, offset=0}, i-signal-in-i-pdu=Harness_HWFoT}
            {data-filter={data-filter-type=ALWAYS, max=1, min=0, offset=0}, i-signal-in-i-pdu=Harness_HWVoltLower}
            {data-filter={data-filter-type=ALWAYS, max=1, min=0, offset=0}, i-signal-in-i-pdu=Harness_HWFoB}
            {data-filter={data-filter-type=NEW-IS-WITHIN, max=65535, min=0}, i-signal-in-i-pdu=Harness_MotorTemp1}
            {data-filter={data-filter-type=NEW-IS-WITHIN, max=65535, min=0}, i-signal-in-i-pdu=Harness_MotorTemp2}
            {data-filter={data-filter-type=ALWAYS, max=255, min=0, offset=0}, i-signal-in-i-pdu=Harness_I_U}
            {data-filter={data-filter-type=ALWAYS, max=255, min=0, offset=0}, i-signal-in-i-pdu=Harness_I_W}
            {data-filter={data-filter-type=ALWAYS, max=255, min=0, offset=0}, i-signal-in-i-pdu=Harness_I_V}
            {data-filter={data-filter-type=ALWAYS, max=255, min=0, offset=0}, i-signal-in-i-pdu=Harness_HVRelayPosVolt}
            {data-filter={data-filter-type=ALWAYS, max=255, min=0}, i-signal-in-i-pdu=MCUMR_Harness_igbt_temp{1..3}}
            {data-filter={data-filter-type=ALWAYS, max=255, min=0}, i-signal-in-i-pdu=MCUMR_Harness_CoolWaterTemp}
            {data-filter={data-filter-type=NEW-IS-WITHIN, max=65535, min=0, offset=0}, i-signal-in-i-pdu=MCUMR_Harness_V_DC}
            {data-filter={data-filter-type=ALWAYS, max=255, min=0, offset=0}, i-signal-in-i-pdu=MCUMR_Harness_PWM_DIR}
            {data-filter={data-filter-type=ALWAYS, max=1, min=0, offset=0}, i-signal-in-i-pdu=MCUMR_Harness_HWRdc}
            {data-filter={data-filter-type=ALWAYS, max=1, min=0, offset=0}, i-signal-in-i-pdu=MCUMR_Harness_HWFoT}
            {data-filter={data-filter-type=ALWAYS, max=1, min=0, offset=0}, i-signal-in-i-pdu=MCUMR_Harness_HWVoltLower}
            {data-filter={data-filter-type=ALWAYS, max=1, min=0, offset=0}, i-signal-in-i-pdu=MCUMR_Harness_HWFoB}
            {data-filter={data-filter-type=NEW-IS-WITHIN, max=65535, min=0}, i-signal-in-i-pdu=MCUMR_Harness_MotorTemp1}
            {data-filter={data-filter-type=NEW-IS-WITHIN, max=65535, min=0}, i-signal-in-i-pdu=MCUMR_Harness_MotorTemp2}
            {data-filter={data-filter-type=ALWAYS, max=255, min=0, offset=0}, i-signal-in-i-pdu=MCUMR_Harness_I_U}
            {data-filter={data-filter-type=ALWAYS, max=255, min=0, offset=0}, i-signal-in-i-pdu=MCUMR_Harness_I_W}
            {data-filter={data-filter-type=ALWAYS, max=255, min=0, offset=0}, i-signal-in-i-pdu=MCUMR_Harness_I_V}
          signal Harness_igbt_temp1: start 0, 8 bit, little-endian, init-value=0, base-type=uint8, implementation-data-type=DT_Harness_igbt_temp1, update-indication-bit-position=-1
          signal Harness_igbt_temp2: start 8, 8 bit, little-endian, init-value=0, base-type=uint8, implementation-data-type=DT_Harness_igbt_temp2, update-indication-bit-position=-1
          signal Harness_igbt_temp3: start 16, 8 bit, little-endian, init-value=0, base-type=uint8, implementation-data-type=DT_Harness_igbt_temp3, update-indication-bit-position=-1
          signal Harness_CoolWaterTemp: start 24, 8 bit, little-endian, init-value=0, base-type=uint8, implementation-data-type=DT_Harness_CoolWaterTemp, update-indication-bit-position=-1
          signal Harness_V_DC: start 32, 16 bit, little-endian, init-value=0, base-type=uint16, implementation-data-type=DT_Harness_V_DC, update-indication-bit-position=-1
          signal Harness_PWM_DIR: start 48, 8 bit, little-endian, init-value=0, base-type=uint8, implementation-data-type=DT_Harness_PWM_DIR, update-indication-bit-position=-1
          signal Harness_HVIL_State: start 57, 1 bit, little-endian, init-value=0, base-type=uint8, implementation-data-type=DT_Harness_HVIL_State, update-indication-bit-position=-1
          signal Harness_crash_err_flag: start 58, 1 bit, little-endian, init-value=0, base-type=uint8, implementation-data-type=DT_Harness_crash_err_flag, update-indication-bit-position=-1
          signal Harness_KeyON: start 59, 1 bit, little-endian, init-value=0, base-type=uint8, implementation-data-type=DT_Harness_KeyON, update-indication-bit-position=-1
          signal Harness_HWRdc: start 60, 1 bit, little-endian, init-value=0, base-type=uint8, implementation-data-type=DT_Harness_HWRdc, update-indication-bit-position=-1
          signal Harness_HWFoT: start 61, 1 bit, little-endian, init-value=0, base-type=uint8, implementation-data-type=DT_Harness_HWFoT, update-indication-bit-position=-1
          signal Harness_HWVoltLower: start 62, 1 bit, little-endian, init-value=0, base-type=uint8, implementation-data-type=DT_Harness_HWVoltLower, update-indication-bit-position=-1
          signal Harness_HWFoB: start 63, 1 bit, little-endian, init-value=0, base-type=uint8, implementation-data-type=DT_Harness_HWFoB, update-indication-bit-position=-1
          signal Harness_MotorTemp1: start 64, 16 bit, little-endian, init-value=0, base-type=uint16, implementation-data-type=DT_Harness_MotorTemp1, update-indication-bit-position=-1
          signal Harness_MotorTemp2: start 80, 16 bit, little-endian, init-value=0, base-type=uint16, implementation-data-type=DT_Harness_MotorTemp2, update-indication-bit-position=-1
          signal Harness_I_U: start 96, 8 bit, little-endian, init-value=0, base-type=uint8, implementation-data-type=DT_Harness_I_U, update-indication-bit-position=-1
          signal Harness_I_W: start 104, 8 bit, little-endian, init-value=0, base-type=uint8, implementation-data-type=DT_Harness_I_W, update-indication-bit-position=-1
          signal Harness_I_V: start 112, 8 bit, little-endian, init-value=0, base-type=uint8, implementation-data-type=DT_Harness_I_V, update-indication-bit-position=-1
          signal Harness_HVRelayPosVolt: start 120, 8 bit, little-endian, init-value=0, base-type=uint8, implementation-data-type=DT_Harness_HVRelayPosVolt, update-indication-bit-position=-1
          signal MCUMR_Harness_igbt_temp1: start 128, 8 bit, little-endian, init-value=0, base-type=uint8, implementation-data-type=DT_MCUMR_Harness_igbt_temp1, update-indication-bit-position=-1
          signal MCUMR_Harness_igbt_temp2: start 136, 8 bit, little-endian, init-value=0, base-type=uint8, implementation-data-type=DT_MCUMR_Harness_igbt_temp2, update-indication-bit-position=-1
          signal MCUMR_Harness_igbt_temp3: start 144, 8 bit, little-endian, init-value=0, base-type=uint8, implementation-data-type=DT_MCUMR_Harness_igbt_temp3, update-indication-bit-position=-1
          signal MCUMR_Harness_CoolWaterTemp: start 152, 8 bit, little-endian, init-value=0, base-type=uint8, implementation-data-type=DT_MCUMR_Harness_CoolWaterTemp, update-indication-bit-position=-1
          signal MCUMR_Harness_V_DC: start 160, 16 bit, little-endian, init-value=0, base-type=uint16, implementation-data-type=DT_MCUMR_Harness_V_DC, update-indication-bit-position=-1
          signal MCUMR_Harness_PWM_DIR: start 176, 8 bit, little-endian, init-value=0, base-type=uint8, implementation-data-type=DT_MCUMR_Harness_PWM_DIR, update-indication-bit-position=-1
          signal MCUMR_Harness_HWRdc: start 184, 1 bit, little-endian, init-value=0, base-type=uint8, implementation-data-type=DT_MCUMR_Harness_HWRdc, update-indication-bit-position=-1
          signal MCUMR_Harness_HWFoT: start 185, 1 bit, little-endian, init-value=0, base-type=uint8, implementation-data-type=DT_MCUMR_Harness_HWFoT, update-indication-bit-position=-1
          signal MCUMR_Harness_HWVoltLower: start 186, 1 bit, little-endian, init-value=0, base-type=uint8, implementation-data-type=DT_MCUMR_Harness_HWVoltLower, update-indication-bit-position=-1
          signal MCUMR_Harness_HWFoB: start 187, 1 bit, little-endian, init-value=0, base-type=uint8, implementation-data-type=DT_MCUMR_Harness_HWFoB, update-indication-bit-position=-1
          signal MCUMR_Harness_MotorTemp1: start 188, 16 bit, little-endian, init-value=0, base-type=uint16, implementation-data-type=DT_MCUMR_Harness_MotorTemp1, update-indication-bit-position=-1
          signal MCUMR_Harness_MotorTemp2: start 204, 16 bit, little-endian, init-value=0, base-type=uint16, implementation-data-type=DT_MCUMR_Harness_MotorTemp2, update-indication-bit-position=-1
          signal MCUMR_Harness_I_U: start 220, 8 bit, little-endian, init-value=0, base-type=uint8, implementation-data-type=DT_MCUMR_Harness_I_U, update-indication-bit-position=-1
          signal MCUMR_Harness_I_W: start 228, 8 bit, little-endian, init-value=0, base-type=uint8, implementation-data-type=DT_MCUMR_Harness_I_W, update-indication-bit-position=-1
          signal MCUMR_Harness_I_V: start 236, 8 bit, little-endian, init-value=0, base-type=uint8, implementation-data-type=DT_MCUMR_Harness_I_V, update-indication-bit-position=-1
      frame UDS_Phy_Tx_729_MCUM: id 0x729, from MVCU, frame-length=64, can-addressing-mode=STANDARD, can-fd-frame-support=true, can-frame-tx-behavior=CAN-FD
        carries pdu UDS_Phy_Tx_729_MCUM: packing-byte-order=big-endian, start-position=7, update-indication-bit-position=-1
        dcm i pdu UDS_Phy_Tx_729_MCUM: length=64, diag-pdu-type=DIAG-RESPONSE
      frame VCU_0x600: id 0x600, from MVCU, frame-length=32, can-addressing-mode=STANDARD, can-fd-frame-support=true, can-frame-tx-behavior=CAN-FD
        carries pdu VCU_0x600: packing-byte-order=little-endian, start-position=0, update-indication-bit-position=-1
        pdu VCU_0x600: length=32, transmission-mode-false-timing=cyclic-timing={time-offset=0.0, time-period=0.2}, transmission-mode-true-timing=cyclic-timing={time-offset=0.0, time-period=0.2}
          transmission-mode-conditions:
            {data-filter={data-filter-type=ALWAYS, max=255, min=0, offset=0}, i-signal-in-i-pdu=VCU_FaultData{0..31}}
          signal VCU_FaultData0: start 0, 8 bit, little-endian, init-value=0, base-type=uint8, implementation-data-type=DT_VCU_FaultData0, update-indication-bit-position=-1
          signal VCU_FaultData1: start 8, 8 bit, little-endian, init-value=0, base-type=uint8, implementation-data-type=DT_VCU_FaultData1, update-indication-bit-position=-1
          signal VCU_FaultData2: start 16, 8 bit, little-endian, init-value=0, base-type=uint8, implementation-data-type=DT_VCU_FaultData2, update-indication-bit-position=-1
          signal VCU_FaultData3: start 24, 8 bit, little-endian, init-value=0, base-type=uint8, implementation-data-type=DT_VCU_FaultData3, update-indication-bit-position=-1
          signal VCU_FaultData4: start 32, 8 bit, little-endian, init-value=0, base-type=uint8, implementation-data-type=DT_VCU_FaultData4, update-indication-bit-position=-1
          signal VCU_FaultData5: start 40, 8 bit, little-endian, init-value=0, base-type=uint8, implementation-data-type=DT_VCU_FaultData5, update-indication-bit-position=-1
          signal VCU_FaultData6: start 48, 8 bit, little-endian, init-value=0, base-type=uint8, implementation-data-type=DT_VCU_FaultData6, update-indication-bit-position=-1
          signal VCU_FaultData7: start 56, 8 bit, little-endian, init-value=0, base-type=uint8, implementation-data-type=DT_VCU_FaultData7, update-indication-bit-position=-1
          signal VCU_FaultData8: start 64, 8 bit, little-endian, init-value=0, base-type=uint8, implementation-data-type=DT_VCU_FaultData8, update-indication-bit-position=-1
          signal VCU_FaultData9: start 72, 8 bit, little-endian, init-value=0, base-type=uint8, implementation-data-type=DT_VCU_FaultData9, update-indication-bit-position=-1
          signal VCU_FaultData10: start 80, 8 bit, little-endian, init-value=0, base-type=uint8, implementation-data-type=DT_VCU_FaultData10, update-indication-bit-position=-1
          signal VCU_FaultData11: start 88, 8 bit, little-endian, init-value=0, base-type=uint8, implementation-data-type=DT_VCU_FaultData11, update-indication-bit-position=-1
          signal VCU_FaultData12: start 96, 8 bit, little-endian, init-value=0, base-type=uint8, implementation-data-type=DT_VCU_FaultData12, update-indication-bit-position=-1
          signal VCU_FaultData13: start 104, 8 bit, little-endian, init-value=0, base-type=uint8, implementation-data-type=DT_VCU_FaultData13, update-indication-bit-position=-1
          signal VCU_FaultData14: start 112, 8 bit, little-endian, init-value=0, base-type=uint8, implementation-data-type=DT_VCU_FaultData14, update-indication-bit-position=-1
          signal VCU_FaultData15: start 120, 8 bit, little-endian, init-value=0, base-type=uint8, implementation-data-type=DT_VCU_FaultData15, update-indication-bit-position=-1
          signal VCU_FaultData16: start 128, 8 bit, little-endian, init-value=0, base-type=uint8, implementation-data-type=DT_VCU_FaultData16, update-indication-bit-position=-1
          signal VCU_FaultData17: start 136, 8 bit, little-endian, init-value=0, base-type=uint8, implementation-data-type=DT_VCU_FaultData17, update-indication-bit-position=-1
          signal VCU_FaultData18: start 144, 8 bit, little-endian, init-value=0, base-type=uint8, implementation-data-type=DT_VCU_FaultData18, update-indication-bit-position=-1
          signal VCU_FaultData19: start 152, 8 bit, little-endian, init-value=0, base-type=uint8, implementation-data-type=DT_VCU_FaultData19, update-indication-bit-position=-1
          signal VCU_FaultData20: start 160, 8 bit, little-endian, init-value=0, base-type=uint8, implementation-data-type=DT_VCU_FaultData20, update-indication-bit-position=-1
          signal VCU_FaultData21: start 168, 8 bit, little-endian, init-value=0, base-type=uint8, implementation-data-type=DT_VCU_FaultData21, update-indication-bit-position=-1
          signal VCU_FaultData22: start 176, 8 bit, little-endian, init-value=0, base-type=uint8, implementation-data-type=DT_VCU_FaultData22, update-indication-bit-position=-1
          signal VCU_FaultData23: start 184, 8 bit, little-endian, init-value=0, base-type=uint8, implementation-data-type=DT_VCU_FaultData23, update-indication-bit-position=-1
          signal VCU_FaultData24: start 192, 8 bit, little-endian, init-value=0, base-type=uint8, implementation-data-type=DT_VCU_FaultData24, update-indication-bit-position=-1
          signal VCU_FaultData25: start 200, 8 bit, little-endian, init-value=0, base-type=uint8, implementation-data-type=DT_VCU_FaultData25, update-indication-bit-position=-1
          signal VCU_FaultData26: start 208, 8 bit, little-endian, init-value=0, base-type=uint8, implementation-data-type=DT_VCU_FaultData26, update-indication-bit-position=-1
          signal VCU_FaultData27: start 216, 8 bit, little-endian, init-value=0, base-type=uint8, implementation-data-type=DT_VCU_FaultData27, update-indication-bit-position=-1
          signal VCU_FaultData28: start 224, 8 bit, little-endian, init-value=0, base-type=uint8, implementation-data-type=DT_VCU_FaultData28, update-indication-bit-position=-1
          signal VCU_FaultData29: start 232, 8 bit, little-endian, init-value=0, base-type=uint8, implementation-data-type=DT_VCU_FaultData29, update-indication-bit-position=-1
          signal VCU_FaultData30: start 240, 8 bit, little-endian, init-value=0, base-type=uint8, implementation-data-type=DT_VCU_FaultData30, update-indication-bit-position=-1
          signal VCU_FaultData31: start 248, 8 bit, little-endian, init-value=0, base-type=uint8, implementation-data-type=DT_VCU_FaultData31, update-indication-bit-position=-1
      frame MCU_0x5C6: id 0x5C6, from MVCU, frame-length=12, can-addressing-mode=STANDARD, can-fd-frame-support=true, can-frame-tx-behavior=CAN-FD
        carries pdu MCU_0x5C6: packing-byte-order=little-endian, start-position=0, update-indication-bit-position=-1
        pdu MCU_0x5C6: length=12, transmission-mode-false-timing=cyclic-timing={time-offset=0.0, time-period=0.01}, transmission-mode-true-timing=cyclic-timing={time-offset=0.0, time-period=0.01}
          transmission-mode-conditions:
            {data-filter={data-filter-type=ALWAYS, max=255, min=0, offset=0}, i-signal-in-i-pdu=MotClb_FaultCode{1..8}}
            {data-filter={data-filter-type=NEW-IS-WITHIN, max=36000, min=0, offset=0}, i-signal-in-i-pdu=MotClb_OfsApply}
            {data-filter={data-filter-type=ALWAYS, max=255, min=0, offset=0}, i-signal-in-i-pdu=MCUMR_MotClb_FaultCode{1..8}}
            {data-filter={data-filter-type=NEW-IS-WITHIN, max=36000, min=0, offset=0}, i-signal-in-i-pdu=MCUMR_MotClb_OfsApply}
          signal MotClb_FaultCode1: start 0, 8 bit, little-endian, init-value=0, base-type=uint8, implementation-data-type=DT_MotClb_FaultCode1, update-indication-bit-position=-1
          signal MotClb_FaultCode2: start 8, 8 bit, little-endian, init-value=0, base-type=uint8, implementation-data-type=DT_MotClb_FaultCode2, update-indication-bit-position=-1
          signal MotClb_FaultCode3: start 16, 8 bit, little-endian, init-value=0, base-type=uint8, implementation-data-type=DT_MotClb_FaultCode3, update-indication-bit-position=-1
          signal MotClb_FaultCode4: start 24, 8 bit, little-endian, init-value=0, base-type=uint8, implementation-data-type=DT_MotClb_FaultCode4, update-indication-bit-position=-1
          signal MotClb_FaultCode5: start 32, 8 bit, little-endian, init-value=0, base-type=uint8, implementation-data-type=DT_MotClb_FaultCode5, update-indication-bit-position=-1
          signal MotClb_FaultCode6: start 40, 8 bit, little-endian, init-value=0, base-type=uint8, implementation-data-type=DT_MotClb_FaultCode6, update-indication-bit-position=-1
          signal MotClb_FaultCode7: start 48, 8 bit, little-endian, init-value=0, base-type=uint8, implementation-data-type=DT_MotClb_FaultCode7, update-indication-bit-position=-1
          signal MotClb_FaultCode8: start 56, 8 bit, little-endian, init-value=0, base-type=uint8, implementation-data-type=DT_MotClb_FaultCode8, update-indication-bit-position=-1
          signal MotClb_OfsApply: start 64, 16 bit, little-endian, init-value=0, base-type=uint16, implementation-data-type=DT_MotClb_OfsApply, update-indication-bit-position=-1
          signal MCUMR_MotClb_FaultCode1: start 0, 8 bit, little-endian, init-value=0, base-type=uint8, implementation-data-type=DT_MCUMR_MotClb_FaultCode1, update-indication-bit-position=-1
          signal MCUMR_MotClb_FaultCode2: start 8, 8 bit, little-endian, init-value=0, base-type=uint8, implementation-data-type=DT_MCUMR_MotClb_FaultCode2, update-indication-bit-position=-1
          signal MCUMR_MotClb_FaultCode3: start 16, 8 bit, little-endian, init-value=0, base-type=uint8, implementation-data-type=DT_MCUMR_MotClb_FaultCode3, update-indication-bit-position=-1
          signal MCUMR_MotClb_FaultCode4: start 24, 8 bit, little-endian, init-value=0, base-type=uint8, implementation-data-type=DT_MCUMR_MotClb_FaultCode4, update-indication-bit-position=-1
          signal MCUMR_MotClb_FaultCode5: start 32, 8 bit, little-endian, init-value=0, base-type=uint8, implementation-data-type=DT_MCUMR_MotClb_FaultCode5, update-indication-bit-position=-1
          signal MCUMR_MotClb_FaultCode6: start 40, 8 bit, little-endian, init-value=0, base-type=uint8, implementation-data-type=DT_MCUMR_MotClb_FaultCode6, update-indication-bit-position=-1
          signal MCUMR_MotClb_FaultCode7: start 48, 8 bit, little-endian, init-value=0, base-type=uint8, implementation-data-type=DT_MCUMR_MotClb_FaultCode7, update-indication-bit-position=-1
          signal MCUMR_MotClb_FaultCode8: start 56, 8 bit, little-endian, init-value=0, base-type=uint8, implementation-data-type=DT_MCUMR_MotClb_FaultCode8, update-indication-bit-position=-1
          signal MCUMR_MotClb_OfsApply: start 64, 16 bit, little-endian, init-value=0, base-type=uint16, implementation-data-type=DT_MCUMR_MotClb_OfsApply, update-indication-bit-position=-1
      frame OBD_Phy_Tx_7EB_MCUM: id 0x7EB, from MVCU, frame-length=8, can-addressing-mode=STANDARD, can-fd-frame-support=true, can-frame-tx-behavior=CAN-20
        carries pdu OBD_Phy_Tx_7EB_MCUM: packing-byte-order=big-endian, start-position=7, update-indication-bit-position=-1
        dcm i pdu OBD_Phy_Tx_7EB_MCUM: length=8, diag-pdu-type=DIAG-RESPONSE
      frame MCU_0x5C4: id 0x5C4, from MVCU, frame-length=32, can-addressing-mode=STANDARD, can-fd-frame-support=true, can-frame-tx-behavior=CAN-FD
        carries pdu MCU_0x5C4: packing-byte-order=little-endian, start-position=0, update-indication-bit-position=-1
        pdu MCU_0x5C4: length=32, transmission-mode-false-timing=cyclic-timing={time-offset=0.0, time-period=0.01}, transmission-mode-true-timing=cyclic-timing={time-offset=0.0, time-period=0.01}
          transmission-mode-conditions:
            {data-filter={data-filter-type=NEW-IS-WITHIN, max=20000, min=0}, i-signal-in-i-pdu=MotClb_UdFb}
            {data-filter={data-filter-type=NEW-IS-WITHIN, max=20000, min=0}, i-signal-in-i-pdu=MotClb_UqFb}
            {data-filter={data-filter-type=NEW-IS-WITHIN, max=20000, min=0}, i-signal-in-i-pdu=MotClb_IdSet}
            {data-filter={data-filter-type=NEW-IS-WITHIN, max=20000, min=0}, i-signal-in-i-pdu=MotClb_IqSet}
            {data-filter={data-filter-type=NEW-IS-WITHIN, max=20000, min=0}, i-signal-in-i-pdu=MotClb_IsCMD_Fb}
            {data-filter={data-filter-type=NEW-IS-WITHIN, max=20000, min=0}, i-signal-in-i-pdu=MotClb_ThetaCMD_Fb}
            {data-filter={data-filter-type=NEW-IS-WITHIN, max=20000, min=0}, i-signal-in-i-pdu=MotClb_Id_Fb}
            {data-filter={data-filter-type=NEW-IS-WITHIN, max=20000, min=0}, i-signal-in-i-pdu=MotClb_Iq_Fb}
            {data-filter={data-filter-type=NEW-IS-WITHIN, max=47000, min=0}, i-signal-in-i-pdu=MotClb_Spd_rpm_Flt}
            {data-filter={data-filter-type=NEW-IS-WITHIN, max=20000, min=0}, i-signal-in-i-pdu=MotClb_ThtSetReal}
            {data-filter={data-filter-type=NEW-IS-WITHIN, max=20000, min=0}, i-signal-in-i-pdu=MotClb_Power_Inverter}
            {data-filter={data-filter-type=NEW-IS-WITHIN, max=65535, min=0, offset=0}, i-signal-in-i-pdu=MotClb_Volt_DC}
            {data-filter={data-filter-type=NEW-IS-WITHIN, max=65535, min=0}, i-signal-in-i-pdu=MotClb_UsOutFlt}
            {data-filter={data-filter-type=NEW-IS-WITHIN, max=65535, min=0}, i-signal-in-i-pdu=MotClb_CoolWater_Temp}
            {data-filter={data-filter-type=ALWAYS, max=255, min=0}, i-signal-in-i-pdu=MotClb_Motor_Temp1_Flt}
            {data-filter={data-filter-type=ALWAYS, max=255, min=0}, i-signal-in-i-pdu=MotClb_IGBT_Temp1}
            {data-filter={data-filter-type=ALWAYS, max=3, min=0, offset=0}, i-signal-in-i-pdu=MotClb_ErrLevel}
            {data-filter={data-filter-type=NEW-IS-WITHIN, max=20000, min=0}, i-signal-in-i-pdu=MCUMR_MotClb_UdFb}
            {data-filter={data-filter-type=NEW-IS-WITHIN, max=20000, min=0}, i-signal-in-i-pdu=MCUMR_MotClb_UqFb}
            {data-filter={data-filter-type=NEW-IS-WITHIN, max=20000, min=0}, i-signal-in-i-pdu=MCUMR_MotClb_IdSet}
            {data-filter={data-filter-type=NEW-IS-WITHIN, max=20000, min=0}, i-signal-in-i-pdu=MCUMR_MotClb_IqSet}
            {data-filter={data-filter-type=NEW-IS-WITHIN, max=20000, min=0}, i-signal-in-i-pdu=MCUMR_MotClb_IsCMD_Fb}
            {data-filter={data-filter-type=NEW-IS-WITHIN, max=20000, min=0}, i-signal-in-i-pdu=MCUMR_MotClb_ThetaCMD_Fb}
            {data-filter={data-filter-type=NEW-IS-WITHIN, max=20000, min=0}, i-signal-in-i-pdu=MCUMR_MotClb_Id_Fb}
            {data-filter={data-filter-type=NEW-IS-WITHIN, max=20000, min=0}, i-signal-in-i-pdu=MCUMR_MotClb_Iq_Fb}
            {data-filter={data-filter-type=NEW-IS-WITHIN, max=47000, min=0}, i-signal-in-i-pdu=MCUMR_MotClb_Spd_rpm_Flt}
            {data-filter={data-filter-type=NEW-IS-WITHIN, max=20000, min=0}, i-signal-in-i-pdu=MCUMR_MotClb_ThtSetReal}
            {data-filter={data-filter-type=NEW-IS-WITHIN, max=20000, min=0}, i-signal-in-i-pdu=MCUMR_MotClb_Power_Inverter}
            {data-filter={data-filter-type=NEW-IS-WITHIN, max=65535, min=0, offset=0}, i-signal-in-i-pdu=MCUMR_MotClb_Volt_DC}
            {data-filter={data-filter-type=NEW-IS-WITHIN, max=65535, min=0}, i-signal-in-i-pdu=MCUMR_MotClb_UsOutFlt}
            {data-filter={data-filter-type=NEW-IS-WITHIN, max=65535, min=0}, i-signal-in-i-pdu=MCUMR_MotClb_CoolWater_Temp}
            {data-filter={data-filter-type=ALWAYS, max=255, min=0}, i-signal-in-i-pdu=MCUMR_MotClb_Motor_Temp1_Flt}
            {data-filter={data-filter-type=ALWAYS, max=255, min=0}, i-signal-in-i-pdu=MCUMR_MotClb_IGBT_Temp1}
            {data-filter={data-filter-type=ALWAYS, max=3, min=0, offset=0}, i-signal-in-i-pdu=MCUMR_MotClb_ErrLevel}
          signal MotClb_UdFb: start 0, 16 bit, little-endian, init-value=0, base-type=uint16, implementation-data-type=DT_MotClb_UdFb, update-indication-bit-position=-1
          signal MotClb_UqFb: start 16, 16 bit, little-endian, init-value=0, base-type=uint16, implementation-data-type=DT_MotClb_UqFb, update-indication-bit-position=-1
          signal MotClb_IdSet: start 32, 16 bit, little-endian, init-value=0, base-type=uint16, implementation-data-type=DT_MotClb_IdSet, update-indication-bit-position=-1
          signal MotClb_IqSet: start 48, 16 bit, little-endian, init-value=0, base-type=uint16, implementation-data-type=DT_MotClb_IqSet, update-indication-bit-position=-1
          signal MotClb_IsCMD_Fb: start 64, 16 bit, little-endian, init-value=0, base-type=uint16, implementation-data-type=DT_MotClb_IsCMD_Fb, update-indication-bit-position=-1
          signal MotClb_ThetaCMD_Fb: start 80, 16 bit, little-endian, init-value=0, base-type=uint16, implementation-data-type=DT_MotClb_ThetaCMD_Fb, update-indication-bit-position=-1
          signal MotClb_Id_Fb: start 96, 16 bit, little-endian, init-value=0, base-type=uint16, implementation-data-type=DT_MotClb_Id_Fb, update-indication-bit-position=-1
          signal MotClb_Iq_Fb: start 112, 16 bit, little-endian, init-value=0, base-type=uint16, implementation-data-type=DT_MotClb_Iq_Fb, update-indication-bit-position=-1
          signal MotClb_Spd_rpm_Flt: start 128, 16 bit, little-endian, init-value=0, base-type=uint16, implementation-data-type=DT_MotClb_Spd_rpm_Flt, update-indication-bit-position=-1
          signal MotClb_ThtSetReal: start 144, 16 bit, little-endian, init-value=0, base-type=uint16, implementation-data-type=DT_MotClb_ThtSetReal, update-indication-bit-position=-1
          signal MotClb_Power_Inverter: start 160, 16 bit, little-endian, init-value=0, base-type=uint16, implementation-data-type=DT_MotClb_Power_Inverter, update-indication-bit-position=-1
          signal MotClb_Volt_DC: start 176, 16 bit, little-endian, init-value=0, base-type=uint16, implementation-data-type=DT_MotClb_Volt_DC, update-indication-bit-position=-1
          signal MotClb_UsOutFlt: start 192, 16 bit, little-endian, init-value=0, base-type=uint16, implementation-data-type=DT_MotClb_UsOutFlt, update-indication-bit-position=-1
          signal MotClb_CoolWater_Temp: start 208, 16 bit, little-endian, init-value=0, base-type=uint16, implementation-data-type=DT_MotClb_CoolWater_Temp, update-indication-bit-position=-1
          signal MotClb_Motor_Temp1_Flt: start 224, 8 bit, little-endian, init-value=0, base-type=uint8, implementation-data-type=DT_MotClb_Motor_Temp1_Flt, update-indication-bit-position=-1
          signal MotClb_IGBT_Temp1: start 232, 8 bit, little-endian, init-value=0, base-type=uint8, implementation-data-type=DT_MotClb_IGBT_Temp1, update-indication-bit-position=-1
          signal MotClb_ErrLevel: start 240, 8 bit, little-endian, init-value=0, base-type=uint8, implementation-data-type=DT_MotClb_ErrLevel, update-indication-bit-position=-1
          signal MCUMR_MotClb_UdFb: start 256, 16 bit, little-endian, init-value=0, base-type=uint16, implementation-data-type=DT_MCUMR_MotClb_UdFb, update-indication-bit-position=-1
          signal MCUMR_MotClb_UqFb: start 272, 16 bit, little-endian, init-value=0, base-type=uint16, implementation-data-type=DT_MCUMR_MotClb_UqFb, update-indication-bit-position=-1
          signal MCUMR_MotClb_IdSet: start 288, 16 bit, little-endian, init-value=0, base-type=uint16, implementation-data-type=DT_MCUMR_MotClb_IdSet, update-indication-bit-position=-1
          signal MCUMR_MotClb_IqSet: start 304, 16 bit, little-endian, init-value=0, base-type=uint16, implementation-data-type=DT_MCUMR_MotClb_IqSet, update-indication-bit-position=-1
          signal MCUMR_MotClb_IsCMD_Fb: start 320, 16 bit, little-endian, init-value=0, base-type=uint16, implementation-data-type=DT_MCUMR_MotClb_IsCMD_Fb, update-indication-bit-position=-1
          signal MCUMR_MotClb_ThetaCMD_Fb: start 336, 16 bit, little-endian, init-value=0, base-type=uint16, implementation-data-type=DT_MCUMR_MotClb_ThetaCMD_Fb, update-indication-bit-position=-1
          signal MCUMR_MotClb_Id_Fb: start 352, 16 bit, little-endian, init-value=0, base-type=uint16, implementation-data-type=DT_MCUMR_MotClb_Id_Fb, update-indication-bit-position=-1
          signal MCUMR_MotClb_Iq_Fb: start 368, 16 bit, little-endian, init-value=0, base-type=uint16, implementation-data-type=DT_MCUMR_MotClb_Iq_Fb, update-indication-bit-position=-1
          signal MCUMR_MotClb_Spd_rpm_Flt: start 384, 16 bit, little-endian, init-value=0, base-type=uint16, implementation-data-type=DT_MCUMR_MotClb_Spd_rpm_Flt, update-indication-bit-position=-1
          signal MCUMR_MotClb_ThtSetReal: start 400, 16 bit, little-endian, init-value=0, base-type=uint16, implementation-data-type=DT_MCUMR_MotClb_ThtSetReal, update-indication-bit-position=-1
          signal MCUMR_MotClb_Power_Inverter: start 416, 16 bit, little-endian, init-value=0, base-type=uint16, implementation-data-type=DT_MCUMR_MotClb_Power_Inverter, update-indication-bit-position=-1
          signal MCUMR_MotClb_Volt_DC: start 432, 16 bit, little-endian, init-value=0, base-type=uint16, implementation-data-type=DT_MCUMR_MotClb_Volt_DC, update-indication-bit-position=-1
          signal MCUMR_MotClb_UsOutFlt: start 448, 16 bit, little-endian, init-value=0, base-type=uint16, implementation-data-type=DT_MCUMR_MotClb_UsOutFlt, update-indication-bit-position=-1
          signal MCUMR_MotClb_CoolWater_Temp: start 464, 16 bit, little-endian, init-value=0, base-type=uint16, implementation-data-type=DT_MCUMR_MotClb_CoolWater_Temp, update-indication-bit-position=-1
          signal MCUMR_MotClb_Motor_Temp1_Flt: start 480, 8 bit, little-endian, init-value=0, base-type=uint8, implementation-data-type=DT_MCUMR_MotClb_Motor_Temp1_Flt, update-indication-bit-position=-1
          signal MCUMR_MotClb_IGBT_Temp1: start 488, 8 bit, little-endian, init-value=0, base-type=uint8, implementation-data-type=DT_MCUMR_MotClb_IGBT_Temp1, update-indication-bit-position=-1
          signal MCUMR_MotClb_ErrLevel: start 496, 8 bit, little-endian, init-value=0, base-type=uint8, implementation-data-type=DT_MCUMR_MotClb_ErrLevel, update-indication-bit-position=-1
      frame VCU_0x13B: id 0x13B, from MVCU, frame-length=32, can-addressing-mode=STANDARD, can-fd-frame-support=true, can-frame-tx-behavior=CAN-FD
        carries pdu VCU_0x13B: packing-byte-order=little-endian, start-position=0, update-indication-bit-position=-1
        pdu VCU_0x13B: length=32, transmission-mode-false-timing=cyclic-timing={time-offset=0.0, time-period=0.01}, transmission-mode-true-timing=cyclic-timing={time-offset=0.0, time-period=0.01}
          transmission-mode-conditions:
            {data-filter={data-filter-type=ALWAYS, max=255, min=0, offset=0}, i-signal-in-i-pdu=VCU_CRC_13B}
            {data-filter={data-filter-type=ALWAYS, max=15, min=0, offset=0}, i-signal-in-i-pdu=VCU_RollingCounter_13B}
            {data-filter={data-filter-type=ALWAYS, max=3, min=0, offset=0}, i-signal-in-i-pdu=VCU_Vehicle_Warning}
            {data-filter={data-filter-type=ALWAYS, max=1, min=0, offset=0}, i-signal-in-i-pdu=VCU_VehicleSts}
            {data-filter={data-filter-type=ALWAYS, max=3, min=0, offset=0}, i-signal-in-i-pdu=VCU_GearLevelPosSts}
            {data-filter={data-filter-type=ALWAYS, max=1, min=0, offset=0}, i-signal-in-i-pdu=VCU_GearLeverValid}
            {data-filter={data-filter-type=ALWAYS, max=1, min=0, offset=0}, i-signal-in-i-pdu=VCU_AccPedalValid}
            {data-filter={data-filter-type=ALWAYS, max=254, min=0, offset=0}, i-signal-in-i-pdu=VCU_ThrottlePosition}
            {data-filter={data-filter-type=ALWAYS, max=1, min=0, offset=0}, i-signal-in-i-pdu=VCU_BMSMainRelayR_Cmd}
            {data-filter={data-filter-type=ALWAYS, max=1, min=0, offset=0}, i-signal-in-i-pdu=VCU_BMSMainRelayF_Cmd}
            {data-filter={data-filter-type=ALWAYS, max=1, min=0, offset=0}, i-signal-in-i-pdu=VCU_BMSEmergencyCmd}
            {data-filter={data-filter-type=ALWAYS, max=1, min=0, offset=0}, i-signal-in-i-pdu=VCU_MCUMActiveReleaseCmd}
            {data-filter={data-filter-type=ALWAYS, max=1, min=0, offset=0}, i-signal-in-i-pdu=VCU_MCUSActiveReleaseCmd}
            {data-filter={data-filter-type=ALWAYS, max=1, min=0, offset=0}, i-signal-in-i-pdu=VCU_AlwACChargeInventerSts}
            {data-filter={data-filter-type=ALWAYS, max=1, min=0, offset=0}, i-signal-in-i-pdu=VCU_AlwDCChargeSts}
            {data-filter={data-filter-type=ALWAYS, max=1, min=0, offset=0}, i-signal-in-i-pdu=VCU_ChargePauseReq}
            {data-filter={data-filter-type=ALWAYS, max=1, min=0, offset=0}, i-signal-in-i-pdu=VCU_SuppressJitterMCUSRequest}
            {data-filter={data-filter-type=ALWAYS, max=1, min=0, offset=0}, i-signal-in-i-pdu=VCU_DCDCEnableCmd}
            {data-filter={data-filter-type=ALWAYS, max=3, min=0, offset=0}, i-signal-in-i-pdu=VCU_ACOffReq}
            {data-filter={data-filter-type=ALWAYS, max=1, min=0, offset=0}, i-signal-in-i-pdu=VCU_VehicleDirect}
            {data-filter={data-filter-type=ALWAYS, max=1, min=0, offset=0}, i-signal-in-i-pdu=VCU_BrakeSysFault}
            {data-filter={data-filter-type=ALWAYS, max=1, min=0, offset=0}, i-signal-in-i-pdu=VCU_SuppressJitterMCUMRequest}
            {data-filter={data-filter-type=ALWAYS, max=1, min=0, offset=0}, i-signal-in-i-pdu=VCU_MDrvControlMode}
            {data-filter={data-filter-type=ALWAYS, max=254, min=0, offset=0}, i-signal-in-i-pdu=VCU_BrakePedalValue}
            {data-filter={data-filter-type=NEW-IS-WITHIN, max=510, min=0, offset=0}, i-signal-in-i-pdu=VCU_MCUMMaxDischargePower}
            {data-filter={data-filter-type=NEW-IS-WITHIN, max=510, min=0, offset=0}, i-signal-in-i-pdu=VCU_MCUMMaxChargePower}
            {data-filter={data-filter-type=NEW-IS-WITHIN, max=10000, min=0}, i-signal-in-i-pdu=VCU_MDrvRequestTorque}
            {data-filter={data-filter-type=NEW-IS-WITHIN, max=34000, min=0}, i-signal-in-i-pdu=VCU_MDrvRequesSpeed}
            {data-filter={data-filter-type=NEW-IS-WITHIN, max=10000, min=0}, i-signal-in-i-pdu=VCU_SDrvRequestTorque}
            {data-filter={data-filter-type=NEW-IS-WITHIN, max=47000, min=0}, i-signal-in-i-pdu=VCU_SDrvRequesSpeed}
            {data-filter={data-filter-type=ALWAYS, max=1, min=0, offset=0}, i-signal-in-i-pdu=VCU_SVehicleSts}
            {data-filter={data-filter-type=ALWAYS, max=7, min=0, offset=0}, i-signal-in-i-pdu=VCU_VehicleHighVoltModeF}
            {data-filter={data-filter-type=ALWAYS, max=1, min=0, offset=0}, i-signal-in-i-pdu=VCU_SDrvControlMode}
            {data-filter={data-filter-type=ALWAYS, max=3, min=0, offset=0}, i-signal-in-i-pdu=VCU_ON2BRelayReq}
            {data-filter={data-filter-type=ALWAYS, max=1, min=0, offset=0}, i-signal-in-i-pdu=VCU_VehPreHVPwrOffCmd}
            {data-filter={data-filter-type=ALWAYS, max=3, min=0, offset=0}, i-signal-in-i-pdu=VCU_FuelTankLockReq}
            {data-filter={data-filter-type=ALWAYS, max=1, min=0, offset=0}, i-signal-in-i-pdu=VCU_VehicleDirectS}
            {data-filter={data-filter-type=ALWAYS, max=1, min=0, offset=0}, i-signal-in-i-pdu=VCU_VehicleDirectS_VD}
            {data-filter={data-filter-type=ALWAYS, max=255, min=0, offset=0}, i-signal-in-i-pdu=VCU_ACPwrLimited}
            {data-filter={data-filter-type=NEW-IS-WITHIN, max=510, min=0, offset=0}, i-signal-in-i-pdu=VCU_MCUSMaxDischargePower}
            {data-filter={data-filter-type=ALWAYS, max=1, min=0, offset=0}, i-signal-in-i-pdu=VCU_VehicleDirectVD}
            {data-filter={data-filter-type=ALWAYS, max=1, min=0, offset=0}, i-signal-in-i-pdu=VCU_MDrvControlModeVD}
            {data-filter={data-filter-type=ALWAYS, max=1, min=0, offset=0}, i-signal-in-i-pdu=VCU_MDrvRequestTorqueVD}
            {data-filter={data-filter-type=ALWAYS, max=1, min=0, offset=0}, i-signal-in-i-pdu=VCU_MDrvRequesSpeedVD}
            {data-filter={data-filter-type=ALWAYS, max=1, min=0, offset=0}, i-signal-in-i-pdu=VCU_SDrvRequestTorqueVD}
            {data-filter={data-filter-type=ALWAYS, max=1, min=0, offset=0}, i-signal-in-i-pdu=VCU_SDrvRequesSpeedVD}
            {data-filter={data-filter-type=ALWAYS, max=1, min=0, offset=0}, i-signal-in-i-pdu=VCU_SDrvControlModeVD}
            {data-filter={data-filter-type=NEW-IS-WITHIN, max=510, min=0, offset=0}, i-signal-in-i-pdu=VCU_MCUSMaxChargePower}
            {data-filter={data-filter-type=ALWAYS, max=7, min=0, offset=0}, i-signal-in-i-pdu=VCU_VehicleHighVoltMode}
            {data-filter={data-filter-type=ALWAYS, max=1, min=0, offset=0}, i-signal-in-i-pdu=VCU_PDUHVIL_Sts}
            {data-filter={data-filter-type=ALWAYS, max=1, min=0, offset=0}, i-signal-in-i-pdu=VCU_PDU220VRelay_Req}
            {data-filter={data-filter-type=ALWAYS, max=1, min=0, offset=0}, i-signal-in-i-pdu=VCU_Cab220VRelay_Req}
            {data-filter={data-filter-type=ALWAYS, max=1, min=0, offset=0}, i-signal-in-i-pdu=VCU_Cabin220VRelay_Req}
            {data-filter={data-filter-type=ALWAYS, max=1, min=0, offset=0}, i-signal-in-i-pdu=VCU_Alw_Cab220VInverter_Sts}
            {data-filter={data-filter-type=ALWAYS, max=1, min=0, offset=0}, i-signal-in-i-pdu=VCU_Alw_Cabin220VInverter_Sts}
            {data-filter={data-filter-type=ALWAYS, max=100, min=0, offset=0}, i-signal-in-i-pdu=VCU_MCUMDampgLmtFactor}
            {data-filter={data-filter-type=ALWAYS, max=100, min=0, offset=0}, i-signal-in-i-pdu=VCU_MCUSDampgLmtFactor}
            {data-filter={data-filter-type=ALWAYS, max=3, min=0, offset=0}, i-signal-in-i-pdu=VCU_BCM_Authentication_Sts}
            {data-filter={data-filter-type=ALWAYS, max=1, min=0, offset=0}, i-signal-in-i-pdu=VCU_AuthenticationKey_WSts}
            {data-filter={data-filter-type=ALWAYS, max=1, min=0, offset=0}, i-signal-in-i-pdu=VCU_BrakePedalSts_P}
            {data-filter={data-filter-type=ALWAYS, max=1, min=0, offset=0}, i-signal-in-i-pdu=VCU_BrakePedalStsValid_P}
            {data-filter={data-filter-type=ALWAYS, max=50, min=0, offset=0}, i-signal-in-i-pdu=VCU_MCUSMaxPosDampgTrq}
            {data-filter={data-filter-type=ALWAYS, max=50, min=0}, i-signal-in-i-pdu=VCU_MCUSMaxNegDampgTrq}
            {data-filter={data-filter-type=ALWAYS, max=50, min=0, offset=0}, i-signal-in-i-pdu=VCU_MCUMMaxPosDampgTrq}
            {data-filter={data-filter-type=ALWAYS, max=50, min=0}, i-signal-in-i-pdu=VCU_MCUMMaxNegDampgTrq}
          signal VCU_CRC_13B: start 0, 8 bit, little-endian, init-value=0, base-type=uint8, implementation-data-type=DT_VCU_CRC_13B, update-indication-bit-position=-1
          signal VCU_RollingCounter_13B: start 8, 4 bit, little-endian, init-value=0, base-type=uint8, implementation-data-type=DT_VCU_RollingCounter_13B, update-indication-bit-position=-1
          signal VCU_Vehicle_Warning: start 16, 2 bit, little-endian, init-value=0, base-type=uint8, implementation-data-type=DT_VCU_Vehicle_Warning, update-indication-bit-position=-1
          signal VCU_VehicleSts: start 18, 1 bit, little-endian, init-value=0, base-type=uint8, implementation-data-type=DT_VCU_VehicleSts, update-indication-bit-position=-1
          signal VCU_GearLevelPosSts: start 19, 2 bit, little-endian, init-value=0, base-type=uint8, implementation-data-type=DT_VCU_GearLevelPosSts, update-indication-bit-position=-1
          signal VCU_GearLeverValid: start 21, 1 bit, little-endian, init-value=0, base-type=uint8, implementation-data-type=DT_VCU_GearLeverValid, update-indication-bit-position=-1
          signal VCU_AccPedalValid: start 23, 1 bit, little-endian, init-value=0, base-type=uint8, implementation-data-type=DT_VCU_AccPedalValid, update-indication-bit-position=-1
          signal VCU_ThrottlePosition: start 24, 8 bit, little-endian, init-value=0, base-type=uint8, implementation-data-type=DT_VCU_ThrottlePosition, update-indication-bit-position=-1
          signal VCU_BMSMainRelayR_Cmd: start 32, 1 bit, little-endian, init-value=0, base-type=uint8, implementation-data-type=DT_VCU_BMSMainRelayR_Cmd, update-indication-bit-position=-1
          signal VCU_BMSMainRelayF_Cmd: start 33, 1 bit, little-endian, init-value=0, base-type=uint8, implementation-data-type=DT_VCU_BMSMainRelayF_Cmd, update-indication-bit-position=-1
          signal VCU_BMSEmergencyCmd: start 34, 1 bit, little-endian, init-value=0, base-type=uint8, implementation-data-type=DT_VCU_BMSEmergencyCmd, update-indication-bit-position=-1
          signal VCU_MCUMActiveReleaseCmd: start 35, 1 bit, little-endian, init-value=0, base-type=uint8, implementation-data-type=DT_VCU_MCUMActiveReleaseCmd, update-indication-bit-position=-1
          signal VCU_MCUSActiveReleaseCmd: start 36, 1 bit, little-endian, init-value=0, base-type=uint8, implementation-data-type=DT_VCU_MCUSActiveReleaseCmd, update-indication-bit-position=-1
          signal VCU_AlwACChargeInventerSts: start 37, 1 bit, little-endian, init-value=0, base-type=uint8, implementation-data-type=DT_VCU_AlwACChargeInventerSts, update-indication-bit-position=-1
          signal VCU_AlwDCChargeSts: start 38, 1 bit, little-endian, init-value=0, base-type=uint8, implementation-data-type=DT_VCU_AlwDCChargeSts, update-indication-bit-position=-1
          signal VCU_ChargePauseReq: start 39, 1 bit, little-endian, init-value=0, base-type=uint8, implementation-data-type=DT_VCU_ChargePauseReq, update-indication-bit-position=-1
          signal VCU_SuppressJitterMCUSRequest: start 40, 1 bit, little-endian, init-value=0, base-type=uint8, implementation-data-type=DT_VCU_SuppressJitterMCUSRequest, update-indication-bit-position=-1
          signal VCU_DCDCEnableCmd: start 41, 1 bit, little-endian, init-value=0, base-type=uint8, implementation-data-type=DT_VCU_DCDCEnableCmd, update-indication-bit-position=-1
          signal VCU_ACOffReq: start 42, 2 bit, little-endian, init-value=0, base-type=uint8, implementation-data-type=DT_VCU_ACOffReq, update-indication-bit-position=-1
          signal VCU_VehicleDirect: start 44, 1 bit, little-endian, init-value=0, base-type=uint8, implementation-data-type=DT_VCU_VehicleDirect, update-indication-bit-position=-1
          signal VCU_BrakeSysFault: start 45, 1 bit, little-endian, init-value=0, base-type=uint8, implementation-data-type=DT_VCU_BrakeSysFault, update-indication-bit-position=-1
          signal VCU_SuppressJitterMCUMRequest: start 46, 1 bit, little-endian, init-value=0, base-type=uint8, implementation-data-type=DT_VCU_SuppressJitterMCUMRequest, update-indication-bit-position=-1
          signal VCU_MDrvControlMode: start 47, 1 bit, little-endian, init-value=0, base-type=uint8, implementation-data-type=DT_VCU_MDrvControlMode, update-indication-bit-position=-1
          signal VCU_BrakePedalValue: start 48, 8 bit, little-endian, init-value=0, base-type=uint8, implementation-data-type=DT_VCU_BrakePedalValue, update-indication-bit-position=-1
          signal VCU_MCUMMaxDischargePower: start 56, 9 bit, little-endian, init-value=0, base-type=uint16, implementation-data-type=DT_VCU_MCUMMaxDischargePower, update-indication-bit-position=-1
          signal VCU_MCUMMaxChargePower: start 71, 9 bit, little-endian, init-value=0, base-type=uint16, implementation-data-type=DT_VCU_MCUMMaxChargePower, update-indication-bit-position=-1
          signal VCU_MDrvRequestTorque: start 80, 16 bit, little-endian, init-value=0, base-type=uint16, implementation-data-type=DT_VCU_MDrvRequestTorque, update-indication-bit-position=-1
          signal VCU_MDrvRequesSpeed: start 96, 16 bit, little-endian, init-value=0, base-type=uint16, implementation-data-type=DT_VCU_MDrvRequesSpeed, update-indication-bit-position=-1
          signal VCU_SDrvRequestTorque: start 112, 16 bit, little-endian, init-value=0, base-type=uint16, implementation-data-type=DT_VCU_SDrvRequestTorque, update-indication-bit-position=-1
          signal VCU_SDrvRequesSpeed: start 128, 16 bit, little-endian, init-value=0, base-type=uint16, implementation-data-type=DT_VCU_SDrvRequesSpeed, update-indication-bit-position=-1
          signal VCU_SVehicleSts: start 144, 1 bit, little-endian, init-value=0, base-type=uint8, implementation-data-type=DT_VCU_SVehicleSts, update-indication-bit-position=-1
          signal VCU_VehicleHighVoltModeF: start 145, 3 bit, little-endian, init-value=0, base-type=uint8, implementation-data-type=DT_VCU_VehicleHighVoltModeF, update-indication-bit-position=-1
          signal VCU_SDrvControlMode: start 148, 1 bit, little-endian, init-value=0, base-type=uint8, implementation-data-type=DT_VCU_SDrvControlMode, update-indication-bit-position=-1
          signal VCU_ON2BRelayReq: start 149, 2 bit, little-endian, init-value=0, base-type=uint8, implementation-data-type=DT_VCU_ON2BRelayReq, update-indication-bit-position=-1
          signal VCU_VehPreHVPwrOffCmd: start 151, 1 bit, little-endian, init-value=0, base-type=uint8, implementation-data-type=DT_VCU_VehPreHVPwrOffCmd, update-indication-bit-position=-1
          signal VCU_FuelTankLockReq: start 152, 2 bit, little-endian, init-value=0, base-type=uint8, implementation-data-type=DT_VCU_FuelTankLockReq, update-indication-bit-position=-1
          signal VCU_VehicleDirectS: start 154, 1 bit, little-endian, init-value=0, base-type=uint8, implementation-data-type=DT_VCU_VehicleDirectS, update-indication-bit-position=-1
          signal VCU_VehicleDirectS_VD: start 155, 1 bit, little-endian, init-value=0, base-type=uint8, implementation-data-type=DT_VCU_VehicleDirectS_VD, update-indication-bit-position=-1
          signal VCU_ACPwrLimited: start 160, 8 bit, little-endian, init-value=0, base-type=uint8, implementation-data-type=DT_VCU_ACPwrLimited, update-indication-bit-position=-1
          signal VCU_MCUSMaxDischargePower: start 168, 9 bit, little-endian, init-value=0, base-type=uint16, implementation-data-type=DT_VCU_MCUSMaxDischargePower, update-indication-bit-position=-1
          signal VCU_VehicleDirectVD: start 177, 1 bit, little-endian, init-value=0, base-type=uint8, implementation-data-type=DT_VCU_VehicleDirectVD, update-indication-bit-position=-1
          signal VCU_MDrvControlModeVD: start 178, 1 bit, little-endian, init-value=0, base-type=uint8, implementation-data-type=DT_VCU_MDrvControlModeVD, update-indication-bit-position=-1
          signal VCU_MDrvRequestTorqueVD: start 179, 1 bit, little-endian, init-value=0, base-type=uint8, implementation-data-type=DT_VCU_MDrvRequestTorqueVD, update-indication-bit-position=-1
          signal VCU_MDrvRequesSpeedVD: start 180, 1 bit, little-endian, init-value=0, base-type=uint8, implementation-data-type=DT_VCU_MDrvRequesSpeedVD, update-indication-bit-position=-1
          signal VCU_SDrvRequestTorqueVD: start 181, 1 bit, little-endian, init-value=0, base-type=uint8, implementation-data-type=DT_VCU_SDrvRequestTorqueVD, update-indication-bit-position=-1
          signal VCU_SDrvRequesSpeedVD: start 182, 1 bit, little-endian, init-value=0, base-type=uint8, implementation-data-type=DT_VCU_SDrvRequesSpeedVD, update-indication-bit-position=-1
          signal VCU_SDrvControlModeVD: start 183, 1 bit, little-endian, init-value=0, base-type=uint8, implementation-data-type=DT_VCU_SDrvControlModeVD, update-indication-bit-position=-1
          signal VCU_MCUSMaxChargePower: start 184, 9 bit, little-endian, init-value=0, base-type=uint16, implementation-data-type=DT_VCU_MCUSMaxChargePower, update-indication-bit-position=-1
          signal VCU_VehicleHighVoltMode: start 193, 3 bit, little-endian, init-value=0, base-type=uint8, implementation-data-type=DT_VCU_VehicleHighVoltMode, update-indication-bit-position=-1
          signal VCU_PDUHVIL_Sts: start 196, 1 bit, little-endian, init-value=0, base-type=uint8, implementation-data-type=DT_VCU_PDUHVIL_Sts, update-indication-bit-position=-1
          signal VCU_PDU220VRelay_Req: start 197, 1 bit, little-endian, init-value=0, base-type=uint8, implementation-data-type=DT_VCU_PDU220VRelay_Req, update-indication-bit-position=-1
          signal VCU_Cab220VRelay_Req: start 198, 1 bit, little-endian, init-value=0, base-type=uint8, implementation-data-type=DT_VCU_Cab220VRelay_Req, update-indication-bit-position=-1
          signal VCU_Cabin220VRelay_Req: start 199, 1 bit, little-endian, init-value=0, base-type=uint8, implementation-data-type=DT_VCU_Cabin220VRelay_Req, update-indication-bit-position=-1
          signal VCU_Alw_Cab220VInverter_Sts: start 200, 1 bit, little-endian, init-value=0, base-type=uint8, implementation-data-type=DT_VCU_Alw_Cab220VInverter_Sts, update-indication-bit-position=-1
          signal VCU_Alw_Cabin220VInverter_Sts: start 201, 1 bit, little-endian, init-value=0, base-type=uint8, implementation-data-type=DT_VCU_Alw_Cabin220VInverter_Sts, update-indication-bit-position=-1
          signal VCU_MCUMDampgLmtFactor: start 202, 7 bit, little-endian, init-value=0, base-type=uint8, implementation-data-type=DT_VCU_MCUMDampgLmtFactor, update-indication-bit-position=-1
          signal VCU_MCUSDampgLmtFactor: start 209, 7 bit, little-endian, init-value=0, base-type=uint8, implementation-data-type=DT_VCU_MCUSDampgLmtFactor, update-indication-bit-position=-1
          signal VCU_BCM_Authentication_Sts: start 216, 2 bit, little-endian, init-value=0, base-type=uint8, implementation-data-type=DT_VCU_BCM_Authentication_Sts, update-indication-bit-position=-1
          signal VCU_AuthenticationKey_WSts: start 218, 1 bit, little-endian, init-value=0, base-type=uint8, implementation-data-type=DT_VCU_AuthenticationKey_WSts, update-indication-bit-position=-1
          signal VCU_BrakePedalSts_P: start 219, 1 bit, little-endian, init-value=0, base-type=uint8, implementation-data-type=DT_VCU_BrakePedalSts_P, update-indication-bit-position=-1
          signal VCU_BrakePedalStsValid_P: start 220, 1 bit, little-endian, init-value=0, base-type=uint8, implementation-data-type=DT_VCU_BrakePedalStsValid_P, update-indication-bit-position=-1
          signal VCU_MCUSMaxPosDampgTrq: start 232, 6 bit, little-endian, init-value=0, base-type=uint8, implementation-data-type=DT_VCU_MCUSMaxPosDampgTrq, update-indication-bit-position=-1
          signal VCU_MCUSMaxNegDampgTrq: start 238, 6 bit, little-endian, init-value=0, base-type=uint8, implementation-data-type=DT_VCU_MCUSMaxNegDampgTrq, update-indication-bit-position=-1
          signal VCU_MCUMMaxPosDampgTrq: start 244, 6 bit, little-endian, init-value=0, base-type=uint8, implementation-data-type=DT_VCU_MCUMMaxPosDampgTrq, update-indication-bit-position=-1
          signal VCU_MCUMMaxNegDampgTrq: start 250, 6 bit, little-endian, init-value=0, base-type=uint8, implementation-data-type=DT_VCU_MCUMMaxNegDampgTrq, update-indication-bit-position=-1
          signal VCU_BoostMode_Fail: start 221, 3 bit, little-endian, init-value=0, base-type=uint8, update-indication-bit-position=-1
          signal VCU_BoostModeSts: start 224, 2 bit, little-endian, init-value=0, base-type=uint8, update-indication-bit-position=-1
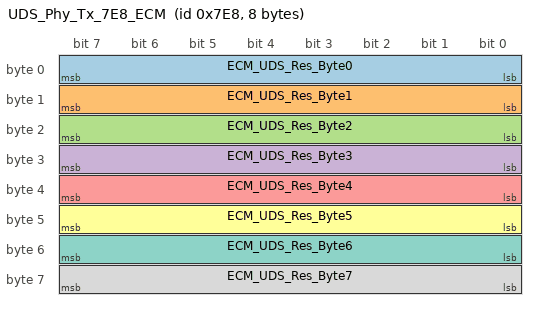
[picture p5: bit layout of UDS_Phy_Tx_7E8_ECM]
      frame UDS_Phy_Tx_7E8_ECM: id 0x7E8, from MVCU, frame-length=8, can-addressing-mode=STANDARD, can-fd-frame-support=true, can-frame-tx-behavior=CAN-20
        carries pdu UDS_Phy_Tx_7E8_ECM: packing-byte-order=little-endian, start-position=0, update-indication-bit-position=-1
        pdu UDS_Phy_Tx_7E8_ECM: length=8
          transmission-mode-conditions:
            {data-filter={data-filter-type=ALWAYS, max=1, min=0, offset=0}, i-signal-in-i-pdu=ECM_UDS_Res_Byte{0..7}}
          signal ECM_UDS_Res_Byte0: start 0, 8 bit, little-endian, init-value=0, base-type=uint8, implementation-data-type=DT_ECM_UDS_Res_Byte0, update-indication-bit-position=-1
          signal ECM_UDS_Res_Byte1: start 8, 8 bit, little-endian, init-value=0, base-type=uint8, implementation-data-type=DT_ECM_UDS_Res_Byte1, update-indication-bit-position=-1
          signal ECM_UDS_Res_Byte2: start 16, 8 bit, little-endian, init-value=0, base-type=uint8, implementation-data-type=DT_ECM_UDS_Res_Byte2, update-indication-bit-position=-1
          signal ECM_UDS_Res_Byte3: start 24, 8 bit, little-endian, init-value=0, base-type=uint8, implementation-data-type=DT_ECM_UDS_Res_Byte3, update-indication-bit-position=-1
          signal ECM_UDS_Res_Byte4: start 32, 8 bit, little-endian, init-value=0, base-type=uint8, implementation-data-type=DT_ECM_UDS_Res_Byte4, update-indication-bit-position=-1
          signal ECM_UDS_Res_Byte5: start 40, 8 bit, little-endian, init-value=0, base-type=uint8, implementation-data-type=DT_ECM_UDS_Res_Byte5, update-indication-bit-position=-1
          signal ECM_UDS_Res_Byte6: start 48, 8 bit, little-endian, init-value=0, base-type=uint8, implementation-data-type=DT_ECM_UDS_Res_Byte6, update-indication-bit-position=-1
          signal ECM_UDS_Res_Byte7: start 56, 8 bit, little-endian, init-value=0, base-type=uint8, implementation-data-type=DT_ECM_UDS_Res_Byte7, update-indication-bit-position=-1
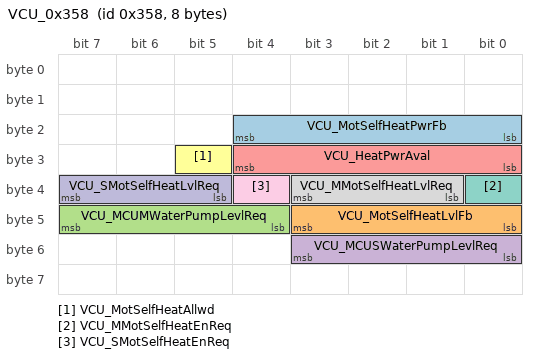
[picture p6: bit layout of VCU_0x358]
      frame VCU_0x358: id 0x358, from MVCU, frame-length=8, can-addressing-mode=STANDARD, can-fd-frame-support=true, can-frame-tx-behavior=CAN-FD
        carries pdu VCU_0x358: packing-byte-order=little-endian, start-position=0, update-indication-bit-position=-1
        pdu VCU_0x358: length=8, transmission-mode-false-timing=cyclic-timing={time-offset=0.0, time-period=0.1}, transmission-mode-true-timing=cyclic-timing={time-offset=0.0, time-period=0.1}
          transmission-mode-conditions:
            {data-filter={data-filter-type=ALWAYS, max=31, min=0, offset=0}, i-signal-in-i-pdu=VCU_MotSelfHeatPwrFb}
            {data-filter={data-filter-type=ALWAYS, max=15, min=0, offset=0}, i-signal-in-i-pdu=VCU_MotSelfHeatLvlFb}
            {data-filter={data-filter-type=ALWAYS, max=15, min=0, offset=0}, i-signal-in-i-pdu=VCU_MCUMWaterPumpLevlReq}
            {data-filter={data-filter-type=ALWAYS, max=15, min=0, offset=0}, i-signal-in-i-pdu=VCU_MCUSWaterPumpLevlReq}
            {data-filter={data-filter-type=ALWAYS, max=31, min=0, offset=0}, i-signal-in-i-pdu=VCU_HeatPwrAval}
            {data-filter={data-filter-type=ALWAYS, max=1, min=0, offset=0}, i-signal-in-i-pdu=VCU_MotSelfHeatAllwd}
            {data-filter={data-filter-type=ALWAYS, max=1, min=0, offset=0}, i-signal-in-i-pdu=VCU_MMotSelfHeatEnReq}
            {data-filter={data-filter-type=ALWAYS, max=7, min=0, offset=0}, i-signal-in-i-pdu=VCU_MMotSelfHeatLvlReq}
            {data-filter={data-filter-type=ALWAYS, max=1, min=0, offset=0}, i-signal-in-i-pdu=VCU_SMotSelfHeatEnReq}
            {data-filter={data-filter-type=ALWAYS, max=7, min=0, offset=0}, i-signal-in-i-pdu=VCU_SMotSelfHeatLvlReq}
          signal VCU_MotSelfHeatPwrFb: start 16, 5 bit, little-endian, init-value=0, base-type=uint8, implementation-data-type=DT_VCU_MotSelfHeatPwrFb, update-indication-bit-position=-1
          signal VCU_MotSelfHeatLvlFb: start 40, 4 bit, little-endian, init-value=0, base-type=uint8, implementation-data-type=DT_VCU_MotSelfHeatLvlFb, update-indication-bit-position=-1
          signal VCU_MCUMWaterPumpLevlReq: start 44, 4 bit, little-endian, init-value=0, base-type=uint8, implementation-data-type=DT_VCU_MCUMWaterPumpLevlReq, update-indication-bit-position=-1
          signal VCU_MCUSWaterPumpLevlReq: start 48, 4 bit, little-endian, init-value=0, base-type=uint8, implementation-data-type=DT_VCU_MCUSWaterPumpLevlReq, update-indication-bit-position=-1
          signal VCU_HeatPwrAval: start 24, 5 bit, little-endian, init-value=0, base-type=uint8, implementation-data-type=DT_VCU_HeatPwrAval, update-indication-bit-position=-1
          signal VCU_MotSelfHeatAllwd: start 29, 1 bit, little-endian, init-value=0, base-type=uint8, implementation-data-type=DT_VCU_MotSelfHeatAllwd, update-indication-bit-position=-1
          signal VCU_MMotSelfHeatEnReq: start 32, 1 bit, little-endian, init-value=0, base-type=uint8, implementation-data-type=DT_VCU_MMotSelfHeatEnReq, update-indication-bit-position=-1
          signal VCU_MMotSelfHeatLvlReq: start 33, 3 bit, little-endian, init-value=0, base-type=uint8, implementation-data-type=DT_VCU_MMotSelfHeatLvlReq, update-indication-bit-position=-1
          signal VCU_SMotSelfHeatEnReq: start 36, 1 bit, little-endian, init-value=0, base-type=uint8, implementation-data-type=DT_VCU_SMotSelfHeatEnReq, update-indication-bit-position=-1
          signal VCU_SMotSelfHeatLvlReq: start 37, 3 bit, little-endian, init-value=0, base-type=uint8, implementation-data-type=DT_VCU_SMotSelfHeatLvlReq, update-indication-bit-position=-1
      frame VCU_0x359: id 0x359, from MVCU, frame-length=16, can-addressing-mode=STANDARD, can-fd-frame-support=true, can-frame-tx-behavior=CAN-FD
        carries pdu VCU_0x359: packing-byte-order=little-endian, start-position=0, update-indication-bit-position=-1
        pdu VCU_0x359: length=16, transmission-mode-false-timing=cyclic-timing={time-offset=0.0, time-period=0.2}, transmission-mode-true-timing=cyclic-timing={time-offset=0.0, time-period=0.2}
          transmission-mode-conditions:
            {data-filter={data-filter-type=ALWAYS, max=1, min=0, offset=0}, i-signal-in-i-pdu=VCU_EolCfg_ESC}
            {data-filter={data-filter-type=ALWAYS, max=1, min=0, offset=0}, i-signal-in-i-pdu=VCU_AbStartupFlag}
            {data-filter={data-filter-type=ALWAYS, max=1, min=0, offset=0}, i-signal-in-i-pdu=VCU_AbResetFlag}
            {data-filter={data-filter-type=ALWAYS, max=1, min=0, offset=0}, i-signal-in-i-pdu=VCU_AbResetlnitFinish}
            {data-filter={data-filter-type=ALWAYS, max=1, min=0, offset=0}, i-signal-in-i-pdu=VCU_EolCfg_EPB}
            {data-filter={data-filter-type=ALWAYS, max=1, min=0, offset=0}, i-signal-in-i-pdu=VCU_EolCfg_AEB}
            {data-filter={data-filter-type=ALWAYS, max=1, min=0, offset=0}, i-signal-in-i-pdu=VCU_EolCfg_InverterFunc}
            {data-filter={data-filter-type=ALWAYS, max=1, min=0, offset=0}, i-signal-in-i-pdu=VCU_EolCfg_APS}
            {data-filter={data-filter-type=ALWAYS, max=7, min=0, offset=0}, i-signal-in-i-pdu=VCU_EolCfg_VehiModels}
            {data-filter={data-filter-type=ALWAYS, max=15, min=0, offset=0}, i-signal-in-i-pdu=VCU_EolCfg_SpdLmtVal}
            {data-filter={data-filter-type=ALWAYS, max=15, min=0, offset=0}, i-signal-in-i-pdu=VCU_EolCfg_WheelType}
            {data-filter={data-filter-type=ALWAYS, max=3, min=0, offset=0}, i-signal-in-i-pdu=VCU_EolCfg_Curise}
            {data-filter={data-filter-type=ALWAYS, max=1, min=0, offset=0}, i-signal-in-i-pdu=VCU_REStartReq}
            {data-filter={data-filter-type=ALWAYS, max=1, min=0, offset=0}, i-signal-in-i-pdu=VCU_REStopReq}
            {data-filter={data-filter-type=ALWAYS, max=1, min=0, offset=0}, i-signal-in-i-pdu=VCU_EolCfg_VehiType}
            {data-filter={data-filter-type=ALWAYS, max=7, min=0, offset=0}, i-signal-in-i-pdu=VCU_EolCfg_MotPwr}
            {data-filter={data-filter-type=ALWAYS, max=255, min=0, offset=0}, i-signal-in-i-pdu=VCU_Vehicle_NVHPwrLimitVal}
            {data-filter={data-filter-type=ALWAYS, max=3, min=0, offset=0}, i-signal-in-i-pdu=VCU_EolCfg_MotDrvStructure}
            {data-filter={data-filter-type=ALWAYS, max=1, min=0, offset=0}, i-signal-in-i-pdu=VCU_WLTCModeFlag}
            {data-filter={data-filter-type=ALWAYS, max=1, min=0, offset=0}, i-signal-in-i-pdu=VCU_EolCfg_RudderDir}
            {data-filter={data-filter-type=ALWAYS, max=3, min=0, offset=0}, i-signal-in-i-pdu=VCU_EolCfg_DCChgRelayPos}
            {data-filter={data-filter-type=ALWAYS, max=1, min=0, offset=0}, i-signal-in-i-pdu=VCU_EolCfg_FPTCIL}
            {data-filter={data-filter-type=ALWAYS, max=1, min=0, offset=0}, i-signal-in-i-pdu=VCU_PWakeupSt}
            {data-filter={data-filter-type=ALWAYS, max=7, min=0, offset=0}, i-signal-in-i-pdu=VCU_SpdLimitReason}
            {data-filter={data-filter-type=ALWAYS, max=3, min=0, offset=0}, i-signal-in-i-pdu=BSW_VertifySts}
            {data-filter={data-filter-type=ALWAYS, max=1, min=0, offset=0}, i-signal-in-i-pdu=VCU_InterAllowEngStart}
            {data-filter={data-filter-type=ALWAYS, max=1, min=0, offset=0}, i-signal-in-i-pdu=VCU_EngineOff_Flag}
            {data-filter={data-filter-type=ALWAYS, max=1, min=0, offset=0}, i-signal-in-i-pdu=VCU_EngineStopAllow}
            {data-filter={data-filter-type=ALWAYS, max=1, min=0, offset=0}, i-signal-in-i-pdu=VCU_EmergencyStopReq}
            {data-filter={data-filter-type=ALWAYS, max=1, min=0, offset=0}, i-signal-in-i-pdu=VCU_EngineAllowStop}
            {data-filter={data-filter-type=ALWAYS, max=250, min=0, offset=0}, i-signal-in-i-pdu=VCU_AdditionalPwrVal}
            {data-filter={data-filter-type=ALWAYS, max=255, min=0, offset=0}, i-signal-in-i-pdu=VCU_VehichRealPwDown}
            {data-filter={data-filter-type=ALWAYS, max=255, min=0, offset=0}, i-signal-in-i-pdu=VCU_IMMOStsResult}
            {data-filter={data-filter-type=ALWAYS, max=255, min=0, offset=0}, i-signal-in-i-pdu=VCU_IMMOStateMachine}
            {data-filter={data-filter-type=ALWAYS, max=255, min=0, offset=0}, i-signal-in-i-pdu=VCU_ShowCarModeNvmResult}
            {data-filter={data-filter-type=ALWAYS, max=255, min=0, offset=0}, i-signal-in-i-pdu=VCU_DeliveryModeNvmData}
            {data-filter={data-filter-type=ALWAYS, max=255, min=0, offset=0}, i-signal-in-i-pdu=VCU_AccPedFaultLvNvmResult}
            {data-filter={data-filter-type=ALWAYS, max=255, min=0, offset=0}, i-signal-in-i-pdu=VCU_VehicleConfigNvmResult}
            {data-filter={data-filter-type=ALWAYS, max=255, min=0, offset=0}, i-signal-in-i-pdu=VCU_EngRunTimeNvmResult}
            {data-filter={data-filter-type=ALWAYS, max=255, min=0, offset=0}, i-signal-in-i-pdu=VCU_IMMOKeyWriteCnt}
            {data-filter={data-filter-type=ALWAYS, max=255}, i-signal-in-i-pdu=VCU_REVehiWheelTrqReq}
            {data-filter={data-filter-type=ALWAYS, max=255}, i-signal-in-i-pdu=VCU_REHighPerformVehiPwr}
            {data-filter={data-filter-type=ALWAYS, max=127}, i-signal-in-i-pdu=VCU_REPwrDampingFactor}
            {data-filter={data-filter-type=ALWAYS, max=511}, i-signal-in-i-pdu=VCU_REDrvTarPwrFit}
          signal VCU_EolCfg_ESC: start 0, 1 bit, little-endian, init-value=0, base-type=uint8, implementation-data-type=DT_VCU_EolCfg_ESC, update-indication-bit-position=-1
          signal VCU_AbStartupFlag: start 47, 1 bit, little-endian, init-value=0, base-type=uint8, implementation-data-type=DT_VCU_AbStartupFlag, update-indication-bit-position=-1
          signal VCU_AbResetFlag: start 46, 1 bit, little-endian, init-value=0, base-type=uint8, implementation-data-type=DT_VCU_AbResetFlag, update-indication-bit-position=-1
          signal VCU_AbResetlnitFinish: start 45, 1 bit, little-endian, init-value=0, base-type=uint8, implementation-data-type=DT_VCU_AbResetlnitFinish, update-indication-bit-position=-1
          signal VCU_EolCfg_EPB: start 1, 1 bit, little-endian, init-value=0, base-type=uint8, implementation-data-type=DT_VCU_EolCfg_EPB, update-indication-bit-position=-1
          signal VCU_EolCfg_AEB: start 2, 1 bit, little-endian, init-value=0, base-type=uint8, implementation-data-type=DT_VCU_EolCfg_AEB, update-indication-bit-position=-1
          signal VCU_EolCfg_InverterFunc: start 3, 1 bit, little-endian, init-value=0, base-type=uint8, implementation-data-type=DT_VCU_EolCfg_InverterFunc, update-indication-bit-position=-1
          signal VCU_EolCfg_APS: start 4, 1 bit, little-endian, init-value=0, base-type=uint8, implementation-data-type=DT_VCU_EolCfg_APS, update-indication-bit-position=-1
          signal VCU_EolCfg_VehiModels: start 5, 3 bit, little-endian, init-value=0, base-type=uint8, implementation-data-type=DT_VCU_EolCfg_VehiModels, update-indication-bit-position=-1
          signal VCU_EolCfg_SpdLmtVal: start 8, 4 bit, little-endian, init-value=0, base-type=uint8, implementation-data-type=DT_VCU_EolCfg_SpdLmtVal, update-indication-bit-position=-1
          signal VCU_EolCfg_WheelType: start 12, 4 bit, little-endian, init-value=0, base-type=uint8, implementation-data-type=DT_VCU_EolCfg_WheelType, update-indication-bit-position=-1
          signal VCU_EolCfg_Curise: start 16, 2 bit, little-endian, init-value=0, base-type=uint8, implementation-data-type=DT_VCU_EolCfg_Curise, update-indication-bit-position=-1
          signal VCU_REStartReq: start 18, 1 bit, little-endian, init-value=0, base-type=uint8, implementation-data-type=DT_VCU_REStartReq, update-indication-bit-position=-1
          signal VCU_REStopReq: start 19, 1 bit, little-endian, init-value=0, base-type=uint8, implementation-data-type=DT_VCU_REStopReq, update-indication-bit-position=-1
          signal VCU_EolCfg_VehiType: start 20, 1 bit, little-endian, init-value=0, base-type=uint8, implementation-data-type=DT_VCU_EolCfg_VehiType, update-indication-bit-position=-1
          signal VCU_EolCfg_MotPwr: start 21, 3 bit, little-endian, init-value=0, base-type=uint8, implementation-data-type=DT_VCU_EolCfg_MotPwr, update-indication-bit-position=-1
          signal VCU_Vehicle_NVHPwrLimitVal: start 24, 8 bit, little-endian, init-value=0, base-type=uint8, implementation-data-type=DT_VCU_Vehicle_NVHPwrLimitVal, update-indication-bit-position=-1
          signal VCU_EolCfg_MotDrvStructure: start 32, 2 bit, little-endian, init-value=0, base-type=uint8, implementation-data-type=DT_VCU_EolCfg_MotDrvStructure, update-indication-bit-position=-1
          signal VCU_WLTCModeFlag: start 34, 1 bit, little-endian, init-value=0, base-type=uint8, implementation-data-type=DT_VCU_WLTCModeFlag, update-indication-bit-position=-1
          signal VCU_EolCfg_RudderDir: start 35, 1 bit, little-endian, init-value=0, base-type=uint8, implementation-data-type=DT_VCU_EolCfg_RudderDir, update-indication-bit-position=-1
          signal VCU_EolCfg_DCChgRelayPos: start 36, 2 bit, little-endian, init-value=0, base-type=uint8, implementation-data-type=DT_VCU_EolCfg_DCChgRelayPos, update-indication-bit-position=-1
          signal VCU_EolCfg_FPTCIL: start 38, 1 bit, little-endian, init-value=0, base-type=uint8, implementation-data-type=DT_VCU_EolCfg_FPTCIL, update-indication-bit-position=-1
          signal VCU_PWakeupSt: start 39, 1 bit, little-endian, init-value=0, base-type=uint8, implementation-data-type=DT_VCU_PWakeupSt, update-indication-bit-position=-1
          signal VCU_SpdLimitReason: start 40, 3 bit, little-endian, init-value=0, base-type=uint8, implementation-data-type=DT_VCU_SpdLimitReason, update-indication-bit-position=-1
          signal BSW_VertifySts: start 43, 2 bit, little-endian, init-value=0, base-type=uint8, implementation-data-type=DT_BSW_VertifySts, update-indication-bit-position=-1
          signal VCU_InterAllowEngStart: start 57, 1 bit, little-endian, init-value=0, base-type=uint8, implementation-data-type=DT_VCU_InterAllowEngStart, update-indication-bit-position=-1
          signal VCU_EngineOff_Flag: start 58, 1 bit, little-endian, init-value=0, base-type=uint8, implementation-data-type=DT_VCU_EngineOff_Flag, update-indication-bit-position=-1
          signal VCU_EngineStopAllow: start 59, 1 bit, little-endian, init-value=0, base-type=uint8, implementation-data-type=DT_VCU_EngineStopAllow, update-indication-bit-position=-1
          signal VCU_EmergencyStopReq: start 60, 1 bit, little-endian, init-value=0, base-type=uint8, implementation-data-type=DT_VCU_EmergencyStopReq, update-indication-bit-position=-1
          signal VCU_IMMOStsResult: start 112, 4 bit, little-endian, init-value=0, base-type=uint8, implementation-data-type=DT_VCU_IMMOStsResult, update-indication-bit-position=-1
          signal VCU_IMMOStateMachine: start 116, 3 bit, little-endian, init-value=0, base-type=uint8, implementation-data-type=DT_VCU_IMMOStateMachine, update-indication-bit-position=-1
          signal VCU_ShowCarModeNvmResult: start 119, 1 bit, little-endian, init-value=0, base-type=uint8, implementation-data-type=DT_VCU_ShowCarModeNvmResult, update-indication-bit-position=-1
          signal VCU_DeliveryModeNvmData: start 120, 1 bit, little-endian, init-value=0, base-type=uint8, implementation-data-type=DT_VCU_DeliveryModeNvmData, update-indication-bit-position=-1
          signal VCU_AccPedFaultLvNvmResult: start 121, 1 bit, little-endian, init-value=0, base-type=uint8, implementation-data-type=DT_VCU_AccPedFaultLvNvmResult, update-indication-bit-position=-1
          signal VCU_VehicleConfigNvmResult: start 122, 1 bit, little-endian, init-value=0, base-type=uint8, implementation-data-type=DT_VCU_VehicleConfigNvmResult, update-indication-bit-position=-1
          signal VCU_EngRunTimeNvmResult: start 123, 1 bit, little-endian, init-value=0, base-type=uint8, implementation-data-type=DT_VCU_EngRunTimeNvmResult, update-indication-bit-position=-1
          signal VCU_IMMOKeyWriteCnt: start 124, 2 bit, little-endian, init-value=0, base-type=uint8, implementation-data-type=DT_VCU_IMMOKeyWriteCnt, update-indication-bit-position=-1
          signal VCU_EngineAllowStop: start 61, 1 bit, little-endian, init-value=0, base-type=uint8, implementation-data-type=DT_VCU_EngineAllowStop, update-indication-bit-position=-1
          signal VCU_REHighPerformVehiPwr: start 72, 8 bit, little-endian, init-value=0, base-type=uint8, implementation-data-type=DT_VCU_REHighPerformVehiPwr, update-indication-bit-position=-1  # ¶¯Á¦ÓÅÏÈÄ¿±êÐèÇó¹¦ÂÊ"
          signal VCU_REPwrDampingFactor: start 80, 7 bit, little-endian, init-value=0, base-type=uint8, implementation-data-type=DT_VCU_REPwrDampingFactor, update-indication-bit-position=-1
          signal VCU_REDrvTarPwrFit: start 87, 9 bit, little-endian, init-value=0, base-type=uint16, implementation-data-type=DT_VCU_REDrvTarPwrFit, update-indication-bit-position=-1
          signal VCU_REVehiWheelTrqReq: start 64, 8 bit, little-endian, init-value=0, base-type=uint8, implementation-data-type=DT_VCU_REVehiWheelTrqReq, update-indication-bit-position=-1  # Ôö³ÌÕû³µÐèÇóÅ¤¾Ø"
          signal VCU_AdditionalPwrVal: start 96, 8 bit, little-endian, init-value=0, base-type=uint8, implementation-data-type=DT_VCU_AdditionalPwrVal, update-indication-bit-position=-1
          signal VCU_VehichRealPwDown: start 104, 8 bit, little-endian, init-value=0, base-type=uint8, implementation-data-type=DT_VCU_VehichRealPwDown, update-indication-bit-position=-1
      frame XCP_Tx_602_VCU: id 0x602, from MVCU, frame-length=8, can-addressing-mode=STANDARD, can-fd-frame-support=true, can-frame-tx-behavior=CAN-20
        carries pdu XCP_Tx_602_VCU: packing-byte-order=big-endian, start-position=7, update-indication-bit-position=-1
        general purpose i pdu XCP_Tx_602_VCU: category=XCP, length=8
